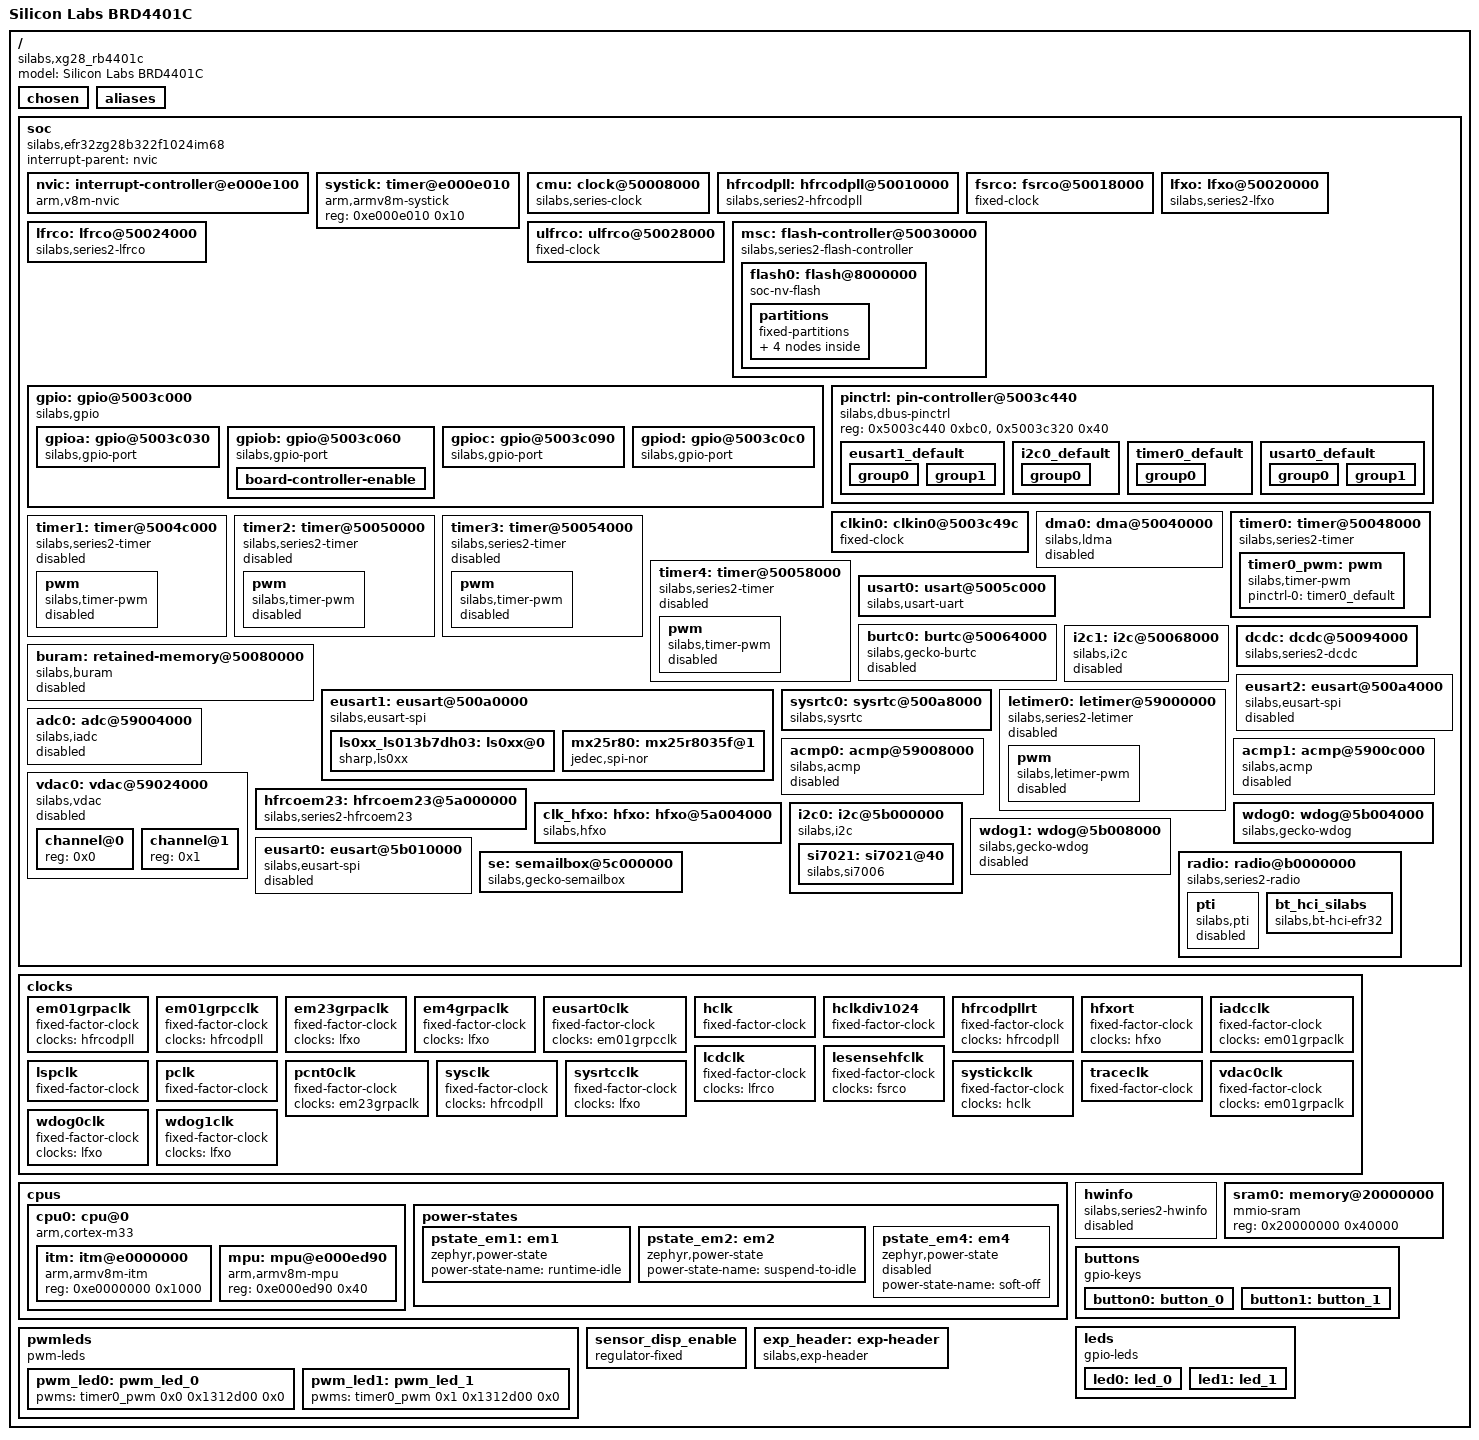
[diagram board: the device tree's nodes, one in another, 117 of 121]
/dts-v1/;

/* node '/' defined in zephyr/dts/common/skeleton.dtsi:9 */
/ {
	#address-cells = < 0x1 >;           /* in zephyr/dts/common/skeleton.dtsi:10 */
	#size-cells = < 0x1 >;              /* in zephyr/dts/common/skeleton.dtsi:11 */
	model = "Silicon Labs BRD4401C";    /* in zephyr/boards/silabs/radio_boards/xg28_rb4401c/xg28_rb4401c.dts:15 */
	compatible = "silabs,xg28_rb4401c",
	             "silabs,efr32zg28";    /* in zephyr/boards/silabs/radio_boards/xg28_rb4401c/xg28_rb4401c.dts:16 */

	/* node '/chosen' defined in zephyr/dts/common/skeleton.dtsi:13 */
	chosen {
		silabs,sleeptimer = &sysrtc0;             /* in zephyr/dts/arm/silabs/xg28/xg28.dtsi:18 */
		zephyr,entropy = &se;                     /* in zephyr/dts/arm/silabs/xg28/xg28.dtsi:19 */
		zephyr,flash-controller = &msc;           /* in zephyr/dts/arm/silabs/xg28/xg28.dtsi:20 */
		zephyr,bt-hci = &bt_hci_silabs;           /* in zephyr/boards/silabs/radio_boards/xg28_rb4401c/xg28_rb4401c.dts:19 */
		zephyr,code-partition = &slot0_partition; /* in zephyr/boards/silabs/radio_boards/xg28_rb4401c/xg28_rb4401c.dts:20 */
		zephyr,console = &usart0;                 /* in zephyr/boards/silabs/radio_boards/xg28_rb4401c/xg28_rb4401c.dts:21 */
		zephyr,display = &ls0xx_ls013b7dh03;      /* in zephyr/boards/silabs/radio_boards/xg28_rb4401c/xg28_rb4401c.dts:22 */
		zephyr,flash = &flash0;                   /* in zephyr/boards/silabs/radio_boards/xg28_rb4401c/xg28_rb4401c.dts:23 */
		zephyr,shell-uart = &usart0;              /* in zephyr/boards/silabs/radio_boards/xg28_rb4401c/xg28_rb4401c.dts:24 */
		zephyr,sram = &sram0;                     /* in zephyr/boards/silabs/radio_boards/xg28_rb4401c/xg28_rb4401c.dts:25 */
		zephyr,uart-pipe = &usart0;               /* in zephyr/boards/silabs/radio_boards/xg28_rb4401c/xg28_rb4401c.dts:26 */
	};

	/* node '/aliases' defined in zephyr/dts/common/skeleton.dtsi:15 */
	aliases {
		dht0 = &si7021;       /* in zephyr/boards/silabs/radio_boards/xg28_rb4401c/xg28_rb4401c.dts:30 */
		led0 = &led0;         /* in zephyr/boards/silabs/radio_boards/xg28_rb4401c/xg28_rb4401c.dts:31 */
		led1 = &led1;         /* in zephyr/boards/silabs/radio_boards/xg28_rb4401c/xg28_rb4401c.dts:32 */
		pwm-led0 = &pwm_led0; /* in zephyr/boards/silabs/radio_boards/xg28_rb4401c/xg28_rb4401c.dts:33 */
		pwm-led1 = &pwm_led1; /* in zephyr/boards/silabs/radio_boards/xg28_rb4401c/xg28_rb4401c.dts:34 */
		sw0 = &button0;       /* in zephyr/boards/silabs/radio_boards/xg28_rb4401c/xg28_rb4401c.dts:35 */
		sw1 = &button1;       /* in zephyr/boards/silabs/radio_boards/xg28_rb4401c/xg28_rb4401c.dts:36 */
		watchdog0 = &wdog0;   /* in zephyr/boards/silabs/radio_boards/xg28_rb4401c/xg28_rb4401c.dts:37 */
	};

	/* node '/soc' defined in zephyr/dts/arm/armv8-m.dtsi:6 */
	soc {
		#address-cells = < 0x1 >;                     /* in zephyr/dts/arm/armv8-m.dtsi:7 */
		#size-cells = < 0x1 >;                        /* in zephyr/dts/arm/armv8-m.dtsi:8 */
		interrupt-parent = < &nvic >;                 /* in zephyr/dts/arm/armv8-m.dtsi:10 */
		ranges;                                       /* in zephyr/dts/arm/armv8-m.dtsi:11 */
		compatible = "silabs,efr32zg28b322f1024im68",
		             "silabs,efr32zg28",
		             "silabs,xg28",
		             "silabs,efr32",
		             "simple-bus";                    /* in zephyr/dts/arm/silabs/xg28/efr32zg28b322f1024im68.dtsi:13 */

		/* node '/soc/interrupt-controller@e000e100' defined in zephyr/dts/arm/armv8-m.dtsi:13 */
		nvic: interrupt-controller@e000e100 {
			#address-cells = < 0x1 >;            /* in zephyr/dts/arm/armv8-m.dtsi:14 */
			compatible = "arm,v8m-nvic";         /* in zephyr/dts/arm/armv8-m.dtsi:15 */
			reg = < 0xe000e100 0xc00 >;          /* in zephyr/dts/arm/armv8-m.dtsi:16 */
			interrupt-controller;                /* in zephyr/dts/arm/armv8-m.dtsi:17 */
			#interrupt-cells = < 0x2 >;          /* in zephyr/dts/arm/armv8-m.dtsi:18 */
			arm,num-irq-priority-bits = < 0x4 >; /* in zephyr/dts/arm/silabs/xg28/xg28.dtsi:668 */
			phandle = < 0x1 >;                   /* in zephyr/dts/arm/armv8-m.dtsi:10 */
		};

		/* node '/soc/timer@e000e010' defined in zephyr/dts/arm/armv8-m.dtsi:21 */
		systick: timer@e000e010 {
			compatible = "arm,armv8m-systick"; /* in zephyr/dts/arm/armv8-m.dtsi:22 */
			reg = < 0xe000e010 0x10 >;         /* in zephyr/dts/arm/armv8-m.dtsi:23 */
		};

		/* node '/soc/clock@50008000' defined in zephyr/dts/arm/silabs/xg28/xg28.dtsi:214 */
		cmu: clock@50008000 {
			compatible = "silabs,series-clock"; /* in zephyr/dts/arm/silabs/xg28/xg28.dtsi:215 */
			reg = < 0x50008000 0x4000 >;        /* in zephyr/dts/arm/silabs/xg28/xg28.dtsi:216 */
			#clock-cells = < 0x2 >;             /* in zephyr/dts/arm/silabs/xg28/xg28.dtsi:217 */
			interrupt-names = "cmu";            /* in zephyr/dts/arm/silabs/xg28/xg28.dtsi:218 */
			interrupts = < 0x30 0x2 >;          /* in zephyr/dts/arm/silabs/xg28/xg28.dtsi:219 */
			status = "okay";                    /* in zephyr/dts/arm/silabs/xg28/xg28.dtsi:220 */
			phandle = < 0x3 >;                  /* in zephyr/dts/arm/silabs/xg28/xg28.dtsi:237 */
		};

		/* node '/soc/hfrcodpll@50010000' defined in zephyr/dts/arm/silabs/xg28/xg28.dtsi:223 */
		hfrcodpll: hfrcodpll@50010000 {
			compatible = "silabs,series2-hfrcodpll"; /* in zephyr/dts/arm/silabs/xg28/xg28.dtsi:224 */
			reg = < 0x50010000 0x4000 >;             /* in zephyr/dts/arm/silabs/xg28/xg28.dtsi:225 */
			#clock-cells = < 0x0 >;                  /* in zephyr/dts/arm/silabs/xg28/xg28.dtsi:226 */
			interrupt-names = "hfrco0";              /* in zephyr/dts/arm/silabs/xg28/xg28.dtsi:228 */
			interrupts = < 0x2e 0x2 >;               /* in zephyr/dts/arm/silabs/xg28/xg28.dtsi:229 */
			clock-frequency = < 0x4a62f80 >;         /* in zephyr/boards/silabs/radio_boards/xg28_rb4401c/xg28_rb4401c.dts:212 */
			clocks = < &hfxo >;                      /* in zephyr/boards/silabs/radio_boards/xg28_rb4401c/xg28_rb4401c.dts:213 */
			dpll-n = < 0xeff >;                      /* in zephyr/boards/silabs/radio_boards/xg28_rb4401c/xg28_rb4401c.dts:214 */
			dpll-m = < 0x77f >;                      /* in zephyr/boards/silabs/radio_boards/xg28_rb4401c/xg28_rb4401c.dts:215 */
			dpll-edge = "fall";                      /* in zephyr/boards/silabs/radio_boards/xg28_rb4401c/xg28_rb4401c.dts:216 */
			dpll-lock = "phase";                     /* in zephyr/boards/silabs/radio_boards/xg28_rb4401c/xg28_rb4401c.dts:217 */
			dpll-autorecover;                        /* in zephyr/boards/silabs/radio_boards/xg28_rb4401c/xg28_rb4401c.dts:218 */
			phandle = < 0xa >;                       /* in zephyr/dts/arm/silabs/xg28/xg28.dtsi:27 */
		};

		/* node '/soc/fsrco@50018000' defined in zephyr/dts/arm/silabs/xg28/xg28.dtsi:232 */
		fsrco: fsrco@50018000 {
			compatible = "fixed-clock";      /* in zephyr/dts/arm/silabs/xg28/xg28.dtsi:233 */
			reg = < 0x50018000 0x4000 >;     /* in zephyr/dts/arm/silabs/xg28/xg28.dtsi:234 */
			#clock-cells = < 0x0 >;          /* in zephyr/dts/arm/silabs/xg28/xg28.dtsi:235 */
			clock-frequency = < 0x1312d00 >; /* in zephyr/dts/arm/silabs/xg28/xg28.dtsi:236 */
			clocks = < &cmu 0x15 0x23 >;     /* in zephyr/dts/arm/silabs/xg28/xg28.dtsi:237 */
			phandle = < 0x11 >;              /* in zephyr/dts/arm/silabs/xg28/xg28.dtsi:95 */
		};

		/* node '/soc/lfxo@50020000' defined in zephyr/dts/arm/silabs/xg28/xg28.dtsi:240 */
		lfxo: lfxo@50020000 {
			compatible = "silabs,series2-lfxo"; /* in zephyr/dts/arm/silabs/xg28/xg28.dtsi:241 */
			reg = < 0x50020000 0x4000 >;        /* in zephyr/dts/arm/silabs/xg28/xg28.dtsi:242 */
			#clock-cells = < 0x0 >;             /* in zephyr/dts/arm/silabs/xg28/xg28.dtsi:243 */
			clock-frequency = < 0x8000 >;       /* in zephyr/dts/arm/silabs/xg28/xg28.dtsi:244 */
			clocks = < &cmu 0x17 0x23 >;        /* in zephyr/dts/arm/silabs/xg28/xg28.dtsi:245 */
			interrupt-names = "lfxo";           /* in zephyr/dts/arm/silabs/xg28/xg28.dtsi:247 */
			interrupts = < 0x17 0x2 >;          /* in zephyr/dts/arm/silabs/xg28/xg28.dtsi:248 */
			timeout = < 0x1000 >;               /* in zephyr/dts/arm/silabs/xg28/xg28.dtsi:250 */
			ctune = < 0x2c >;                   /* in zephyr/boards/silabs/radio_boards/xg28_rb4401c/xg28_rb4401c.dts:228 */
			precision = < 0x32 >;               /* in zephyr/boards/silabs/radio_boards/xg28_rb4401c/xg28_rb4401c.dts:229 */
			status = "okay";                    /* in zephyr/boards/silabs/radio_boards/xg28_rb4401c/xg28_rb4401c.dts:230 */
			phandle = < 0xb >;                  /* in zephyr/boards/silabs/radio_boards/xg28_rb4401c/xg28_rb4401c.dts:127 */
		};

		/* node '/soc/lfrco@50024000' defined in zephyr/dts/arm/silabs/xg28/xg28.dtsi:254 */
		lfrco: lfrco@50024000 {
			compatible = "silabs,series2-lfrco"; /* in zephyr/dts/arm/silabs/xg28/xg28.dtsi:255 */
			reg = < 0x50024000 0x4000 >;         /* in zephyr/dts/arm/silabs/xg28/xg28.dtsi:256 */
			#clock-cells = < 0x0 >;              /* in zephyr/dts/arm/silabs/xg28/xg28.dtsi:257 */
			clock-frequency = < 0x8000 >;        /* in zephyr/dts/arm/silabs/xg28/xg28.dtsi:258 */
			clocks = < &cmu 0x16 0x23 >;         /* in zephyr/dts/arm/silabs/xg28/xg28.dtsi:259 */
			interrupt-names = "lfrco";           /* in zephyr/dts/arm/silabs/xg28/xg28.dtsi:260 */
			interrupts = < 0x18 0x2 >;           /* in zephyr/dts/arm/silabs/xg28/xg28.dtsi:261 */
			phandle = < 0x10 >;                  /* in zephyr/dts/arm/silabs/xg28/xg28.dtsi:89 */
		};

		/* node '/soc/ulfrco@50028000' defined in zephyr/dts/arm/silabs/xg28/xg28.dtsi:264 */
		ulfrco: ulfrco@50028000 {
			compatible = "fixed-clock";  /* in zephyr/dts/arm/silabs/xg28/xg28.dtsi:265 */
			reg = < 0x50028000 0x4000 >; /* in zephyr/dts/arm/silabs/xg28/xg28.dtsi:266 */
			#clock-cells = < 0x0 >;      /* in zephyr/dts/arm/silabs/xg28/xg28.dtsi:267 */
			clock-frequency = < 0x3e8 >; /* in zephyr/dts/arm/silabs/xg28/xg28.dtsi:268 */
			clocks = < &cmu 0x18 0x23 >; /* in zephyr/dts/arm/silabs/xg28/xg28.dtsi:269 */
			interrupt-names = "ulfrco";  /* in zephyr/dts/arm/silabs/xg28/xg28.dtsi:270 */
			interrupts = < 0x19 0x2 >;   /* in zephyr/dts/arm/silabs/xg28/xg28.dtsi:271 */
		};

		/* node '/soc/flash-controller@50030000' defined in zephyr/dts/arm/silabs/xg28/xg28.dtsi:274 */
		msc: flash-controller@50030000 {
			compatible = "silabs,series2-flash-controller"; /* in zephyr/dts/arm/silabs/xg28/xg28.dtsi:275 */
			reg = < 0x50030000 0x4000 >;                    /* in zephyr/dts/arm/silabs/xg28/xg28.dtsi:276 */
			#address-cells = < 0x1 >;                       /* in zephyr/dts/arm/silabs/xg28/xg28.dtsi:277 */
			#size-cells = < 0x1 >;                          /* in zephyr/dts/arm/silabs/xg28/xg28.dtsi:278 */
			clocks = < &cmu 0x50 0x1 >;                     /* in zephyr/dts/arm/silabs/xg28/xg28.dtsi:279 */
			interrupt-names = "msc";                        /* in zephyr/dts/arm/silabs/xg28/xg28.dtsi:280 */
			interrupts = < 0x33 0x2 >;                      /* in zephyr/dts/arm/silabs/xg28/xg28.dtsi:281 */

			/* node '/soc/flash-controller@50030000/flash@8000000' defined in zephyr/dts/arm/silabs/xg28/xg28.dtsi:283 */
			flash0: flash@8000000 {
				compatible = "soc-nv-flash";   /* in zephyr/dts/arm/silabs/xg28/xg28.dtsi:284 */
				erase-block-size = < 0x2000 >; /* in zephyr/dts/arm/silabs/xg28/xg28.dtsi:285 */
				write-block-size = < 0x4 >;    /* in zephyr/dts/arm/silabs/xg28/xg28.dtsi:286 */
				reg = < 0x8000000 0x100000 >;  /* in zephyr/dts/arm/silabs/xg28/efr32zg28b322f1024im68.dtsi:19 */

				/* node '/soc/flash-controller@50030000/flash@8000000/partitions' defined in zephyr/boards/silabs/radio_boards/xg28_rb4401c/xg28_rb4401c.dts:268 */
				partitions {
					compatible = "fixed-partitions"; /* in zephyr/boards/silabs/radio_boards/xg28_rb4401c/xg28_rb4401c.dts:269 */
					#address-cells = < 0x1 >;        /* in zephyr/boards/silabs/radio_boards/xg28_rb4401c/xg28_rb4401c.dts:270 */
					#size-cells = < 0x1 >;           /* in zephyr/boards/silabs/radio_boards/xg28_rb4401c/xg28_rb4401c.dts:271 */

					/* node '/soc/flash-controller@50030000/flash@8000000/partitions/partition@0' defined in zephyr/boards/silabs/radio_boards/xg28_rb4401c/xg28_rb4401c.dts:274 */
					boot_partition: partition@0 {
						reg = < 0x0 0xc000 >; /* in zephyr/boards/silabs/radio_boards/xg28_rb4401c/xg28_rb4401c.dts:275 */
						label = "mcuboot";    /* in zephyr/boards/silabs/radio_boards/xg28_rb4401c/xg28_rb4401c.dts:276 */
						read-only;            /* in zephyr/boards/silabs/radio_boards/xg28_rb4401c/xg28_rb4401c.dts:277 */
					};

					/* node '/soc/flash-controller@50030000/flash@8000000/partitions/partition@c000' defined in zephyr/boards/silabs/radio_boards/xg28_rb4401c/xg28_rb4401c.dts:281 */
					slot0_partition: partition@c000 {
						reg = < 0xc000 0x76000 >; /* in zephyr/boards/silabs/radio_boards/xg28_rb4401c/xg28_rb4401c.dts:282 */
						label = "image-0";        /* in zephyr/boards/silabs/radio_boards/xg28_rb4401c/xg28_rb4401c.dts:283 */
					};

					/* node '/soc/flash-controller@50030000/flash@8000000/partitions/partition@82000' defined in zephyr/boards/silabs/radio_boards/xg28_rb4401c/xg28_rb4401c.dts:287 */
					slot1_partition: partition@82000 {
						reg = < 0x82000 0x76000 >; /* in zephyr/boards/silabs/radio_boards/xg28_rb4401c/xg28_rb4401c.dts:288 */
						label = "image-1";         /* in zephyr/boards/silabs/radio_boards/xg28_rb4401c/xg28_rb4401c.dts:289 */
					};

					/* node '/soc/flash-controller@50030000/flash@8000000/partitions/partition@f8000' defined in zephyr/boards/silabs/radio_boards/xg28_rb4401c/xg28_rb4401c.dts:293 */
					storage_partition: partition@f8000 {
						reg = < 0xf8000 0x8000 >; /* in zephyr/boards/silabs/radio_boards/xg28_rb4401c/xg28_rb4401c.dts:294 */
						label = "storage";        /* in zephyr/boards/silabs/radio_boards/xg28_rb4401c/xg28_rb4401c.dts:295 */
					};
				};
			};
		};

		/* node '/soc/gpio@5003c000' defined in zephyr/dts/arm/silabs/xg28/xg28.dtsi:290 */
		gpio: gpio@5003c000 {
			compatible = "silabs,gpio";    /* in zephyr/dts/arm/silabs/xg28/xg28.dtsi:291 */
			reg = < 0x5003c000 0x4000 >;   /* in zephyr/dts/arm/silabs/xg28/xg28.dtsi:292 */
			ranges;                        /* in zephyr/dts/arm/silabs/xg28/xg28.dtsi:293 */
			#address-cells = < 0x1 >;      /* in zephyr/dts/arm/silabs/xg28/xg28.dtsi:294 */
			#size-cells = < 0x1 >;         /* in zephyr/dts/arm/silabs/xg28/xg28.dtsi:295 */
			clocks = < &cmu 0x1a 0x3 >;    /* in zephyr/dts/arm/silabs/xg28/xg28.dtsi:296 */
			interrupt-names = "gpio_odd",
			                  "gpio_even"; /* in zephyr/dts/arm/silabs/xg28/xg28.dtsi:297 */
			interrupts = < 0x1a 0x2 >,
			             < 0x1b 0x2 >;     /* in zephyr/dts/arm/silabs/xg28/xg28.dtsi:298 */
			status = "okay";               /* in zephyr/boards/silabs/radio_boards/xg28_rb4401c/xg28_rb4401c.dts:186 */

			/* node '/soc/gpio@5003c000/gpio@5003c030' defined in zephyr/dts/arm/silabs/xg28/xg28.dtsi:300 */
			gpioa: gpio@5003c030 {
				compatible = "silabs,gpio-port"; /* in zephyr/dts/arm/silabs/xg28/xg28.dtsi:301 */
				reg = < 0x5003c030 0x30 >;       /* in zephyr/dts/arm/silabs/xg28/xg28.dtsi:302 */
				#gpio-cells = < 0x2 >;           /* in zephyr/dts/arm/silabs/xg28/xg28.dtsi:303 */
				gpio-controller;                 /* in zephyr/dts/arm/silabs/xg28/xg28.dtsi:304 */
				silabs,wakeup-ints = < 0x0 >;    /* in zephyr/dts/arm/silabs/xg28/xg28.dtsi:305 */
				silabs,wakeup-pins = < 0x5 >;    /* in zephyr/dts/arm/silabs/xg28/xg28.dtsi:306 */
				status = "okay";                 /* in zephyr/boards/silabs/radio_boards/xg28_rb4401c/xg28_rb4401c.dts:190 */
				phandle = < 0x1a >;              /* in zephyr/boards/silabs/radio_boards/xg28_rb4401c/xg28_rb4401c.dts:92 */
			};

			/* node '/soc/gpio@5003c000/gpio@5003c060' defined in zephyr/dts/arm/silabs/xg28/xg28.dtsi:310 */
			gpiob: gpio@5003c060 {
				compatible = "silabs,gpio-port"; /* in zephyr/dts/arm/silabs/xg28/xg28.dtsi:311 */
				reg = < 0x5003c060 0x30 >;       /* in zephyr/dts/arm/silabs/xg28/xg28.dtsi:312 */
				#gpio-cells = < 0x2 >;           /* in zephyr/dts/arm/silabs/xg28/xg28.dtsi:313 */
				gpio-controller;                 /* in zephyr/dts/arm/silabs/xg28/xg28.dtsi:314 */
				silabs,wakeup-ints = < 0x3 >,
				                     < 0x4 >;    /* in zephyr/dts/arm/silabs/xg28/xg28.dtsi:315 */
				silabs,wakeup-pins = < 0x1 >,
				                     < 0x3 >;    /* in zephyr/dts/arm/silabs/xg28/xg28.dtsi:316 */
				status = "okay";                 /* in zephyr/boards/silabs/radio_boards/xg28_rb4401c/xg28_rb4401c.dts:194 */
				phandle = < 0x17 >;              /* in zephyr/boards/silabs/radio_boards/xg28_rb4401c/xg28_rb4401c.dts:44 */

				/* node '/soc/gpio@5003c000/gpio@5003c060/board-controller-enable' defined in zephyr/boards/silabs/radio_boards/xg28_rb4401c/xg28_rb4401c.dts:196 */
				board-controller-enable {
					gpio-hog;            /* in zephyr/boards/silabs/radio_boards/xg28_rb4401c/xg28_rb4401c.dts:197 */
					gpios = < 0x0 0x0 >; /* in zephyr/boards/silabs/radio_boards/xg28_rb4401c/xg28_rb4401c.dts:198 */
					output-high;         /* in zephyr/boards/silabs/radio_boards/xg28_rb4401c/xg28_rb4401c.dts:199 */
				};
			};

			/* node '/soc/gpio@5003c000/gpio@5003c090' defined in zephyr/dts/arm/silabs/xg28/xg28.dtsi:320 */
			gpioc: gpio@5003c090 {
				compatible = "silabs,gpio-port"; /* in zephyr/dts/arm/silabs/xg28/xg28.dtsi:321 */
				reg = < 0x5003c090 0x30 >;       /* in zephyr/dts/arm/silabs/xg28/xg28.dtsi:322 */
				#gpio-cells = < 0x2 >;           /* in zephyr/dts/arm/silabs/xg28/xg28.dtsi:323 */
				gpio-controller;                 /* in zephyr/dts/arm/silabs/xg28/xg28.dtsi:324 */
				silabs,wakeup-ints = < 0x6 >,
				                     < 0x7 >,
				                     < 0x8 >;    /* in zephyr/dts/arm/silabs/xg28/xg28.dtsi:325 */
				silabs,wakeup-pins = < 0x0 >,
				                     < 0x5 >,
				                     < 0x7 >;    /* in zephyr/dts/arm/silabs/xg28/xg28.dtsi:326 */
				status = "okay";                 /* in zephyr/boards/silabs/radio_boards/xg28_rb4401c/xg28_rb4401c.dts:204 */
				phandle = < 0x7 >;               /* in zephyr/boards/silabs/radio_boards/xg28_rb4401c/xg28_rb4401c.dts:139 */
			};

			/* node '/soc/gpio@5003c000/gpio@5003c0c0' defined in zephyr/dts/arm/silabs/xg28/xg28.dtsi:330 */
			gpiod: gpio@5003c0c0 {
				compatible = "silabs,gpio-port"; /* in zephyr/dts/arm/silabs/xg28/xg28.dtsi:331 */
				reg = < 0x5003c0c0 0x30 >;       /* in zephyr/dts/arm/silabs/xg28/xg28.dtsi:332 */
				#gpio-cells = < 0x2 >;           /* in zephyr/dts/arm/silabs/xg28/xg28.dtsi:333 */
				gpio-controller;                 /* in zephyr/dts/arm/silabs/xg28/xg28.dtsi:334 */
				silabs,wakeup-ints = < 0xa >,
				                     < 0x9 >;    /* in zephyr/dts/arm/silabs/xg28/xg28.dtsi:335 */
				silabs,wakeup-pins = < 0x5 >,
				                     < 0x2 >;    /* in zephyr/dts/arm/silabs/xg28/xg28.dtsi:336 */
				status = "okay";                 /* in zephyr/boards/silabs/radio_boards/xg28_rb4401c/xg28_rb4401c.dts:208 */
				phandle = < 0x18 >;              /* in zephyr/boards/silabs/radio_boards/xg28_rb4401c/xg28_rb4401c.dts:65 */
			};
		};

		/* node '/soc/pin-controller@5003c440' defined in zephyr/dts/arm/silabs/xg28/xg28.dtsi:341 */
		pinctrl: pin-controller@5003c440 {
			compatible = "silabs,dbus-pinctrl"; /* in zephyr/dts/arm/silabs/xg28/xg28.dtsi:342 */
			reg = < 0x5003c440 0xbc0 >,
			      < 0x5003c320 0x40 >;          /* in zephyr/dts/arm/silabs/xg28/xg28.dtsi:343 */
			reg-names = "dbus",
			            "abus";                 /* in zephyr/dts/arm/silabs/xg28/xg28.dtsi:344 */

			/* node '/soc/pin-controller@5003c440/eusart1_default' defined in zephyr/boards/silabs/radio_boards/xg28_rb4401c/xg28_rb4401c-pinctrl.dtsi:10 */
			eusart1_default: eusart1_default {
				phandle = < 0x6 >; /* in zephyr/boards/silabs/radio_boards/xg28_rb4401c/xg28_rb4401c.dts:137 */

				/* node '/soc/pin-controller@5003c440/eusart1_default/group0' defined in zephyr/boards/silabs/radio_boards/xg28_rb4401c/xg28_rb4401c-pinctrl.dtsi:11 */
				group0 {
					pins = < 0x26242912 >,
					       < 0x251c2932 >; /* in zephyr/boards/silabs/radio_boards/xg28_rb4401c/xg28_rb4401c-pinctrl.dtsi:12 */
					drive-push-pull;       /* in zephyr/boards/silabs/radio_boards/xg28_rb4401c/xg28_rb4401c-pinctrl.dtsi:13 */
					output-high;           /* in zephyr/boards/silabs/radio_boards/xg28_rb4401c/xg28_rb4401c-pinctrl.dtsi:14 */
				};

				/* node '/soc/pin-controller@5003c440/eusart1_default/group1' defined in zephyr/boards/silabs/radio_boards/xg28_rb4401c/xg28_rb4401c-pinctrl.dtsi:17 */
				group1 {
					pins = < 0x24142922 >; /* in zephyr/boards/silabs/radio_boards/xg28_rb4401c/xg28_rb4401c-pinctrl.dtsi:18 */
					input-enable;          /* in zephyr/boards/silabs/radio_boards/xg28_rb4401c/xg28_rb4401c-pinctrl.dtsi:19 */
					silabs,input-filter;   /* in zephyr/boards/silabs/radio_boards/xg28_rb4401c/xg28_rb4401c-pinctrl.dtsi:20 */
				};
			};

			/* node '/soc/pin-controller@5003c440/i2c0_default' defined in zephyr/boards/silabs/radio_boards/xg28_rb4401c/xg28_rb4401c-pinctrl.dtsi:24 */
			i2c0_default: i2c0_default {
				phandle = < 0x8 >; /* in zephyr/boards/silabs/radio_boards/xg28_rb4401c/xg28_rb4401c.dts:174 */

				/* node '/soc/pin-controller@5003c440/i2c0_default/group0' defined in zephyr/boards/silabs/radio_boards/xg28_rb4401c/xg28_rb4401c-pinctrl.dtsi:25 */
				group0 {
					pins = < 0x21043e52 >,
					       < 0x220c3e72 >; /* in zephyr/boards/silabs/radio_boards/xg28_rb4401c/xg28_rb4401c-pinctrl.dtsi:26 */
					drive-open-drain;      /* in zephyr/boards/silabs/radio_boards/xg28_rb4401c/xg28_rb4401c-pinctrl.dtsi:27 */
					bias-pull-up;          /* in zephyr/boards/silabs/radio_boards/xg28_rb4401c/xg28_rb4401c-pinctrl.dtsi:28 */
				};
			};

			/* node '/soc/pin-controller@5003c440/timer0_default' defined in zephyr/boards/silabs/radio_boards/xg28_rb4401c/xg28_rb4401c-pinctrl.dtsi:32 */
			timer0_default: timer0_default {
				phandle = < 0x4 >; /* in zephyr/boards/silabs/radio_boards/xg28_rb4401c/xg28_rb4401c.dts:249 */

				/* node '/soc/pin-controller@5003c440/timer0_default/group0' defined in zephyr/boards/silabs/radio_boards/xg28_rb4401c/xg28_rb4401c-pinctrl.dtsi:33 */
				group0 {
					pins = < 0x2104ae21 >,
					       < 0x220cae33 >; /* in zephyr/boards/silabs/radio_boards/xg28_rb4401c/xg28_rb4401c-pinctrl.dtsi:34 */
					drive-push-pull;       /* in zephyr/boards/silabs/radio_boards/xg28_rb4401c/xg28_rb4401c-pinctrl.dtsi:35 */
					output-high;           /* in zephyr/boards/silabs/radio_boards/xg28_rb4401c/xg28_rb4401c-pinctrl.dtsi:36 */
				};
			};

			/* node '/soc/pin-controller@5003c440/usart0_default' defined in zephyr/boards/silabs/radio_boards/xg28_rb4401c/xg28_rb4401c-pinctrl.dtsi:40 */
			usart0_default: usart0_default {
				phandle = < 0x5 >; /* in zephyr/boards/silabs/radio_boards/xg28_rb4401c/xg28_rb4401c.dts:168 */

				/* node '/soc/pin-controller@5003c440/usart0_default/group0' defined in zephyr/boards/silabs/radio_boards/xg28_rb4401c/xg28_rb4401c-pinctrl.dtsi:41 */
				group0 {
					pins = < 0x2624d680 >; /* in zephyr/boards/silabs/radio_boards/xg28_rb4401c/xg28_rb4401c-pinctrl.dtsi:42 */
					drive-push-pull;       /* in zephyr/boards/silabs/radio_boards/xg28_rb4401c/xg28_rb4401c-pinctrl.dtsi:43 */
					output-high;           /* in zephyr/boards/silabs/radio_boards/xg28_rb4401c/xg28_rb4401c-pinctrl.dtsi:44 */
				};

				/* node '/soc/pin-controller@5003c440/usart0_default/group1' defined in zephyr/boards/silabs/radio_boards/xg28_rb4401c/xg28_rb4401c-pinctrl.dtsi:47 */
				group1 {
					pins = < 0x2414d690 >; /* in zephyr/boards/silabs/radio_boards/xg28_rb4401c/xg28_rb4401c-pinctrl.dtsi:48 */
					input-enable;          /* in zephyr/boards/silabs/radio_boards/xg28_rb4401c/xg28_rb4401c-pinctrl.dtsi:49 */
					silabs,input-filter;   /* in zephyr/boards/silabs/radio_boards/xg28_rb4401c/xg28_rb4401c-pinctrl.dtsi:50 */
				};
			};
		};

		/* node '/soc/clkin0@5003c49c' defined in zephyr/dts/arm/silabs/xg28/xg28.dtsi:347 */
		clkin0: clkin0@5003c49c {
			compatible = "fixed-clock";      /* in zephyr/dts/arm/silabs/xg28/xg28.dtsi:348 */
			reg = < 0x5003c49c 0x4 >;        /* in zephyr/dts/arm/silabs/xg28/xg28.dtsi:349 */
			#clock-cells = < 0x0 >;          /* in zephyr/dts/arm/silabs/xg28/xg28.dtsi:350 */
			clock-frequency = < 0x243d580 >; /* in zephyr/dts/arm/silabs/xg28/xg28.dtsi:351 */
		};

		/* node '/soc/dma@50040000' defined in zephyr/dts/arm/silabs/xg28/xg28.dtsi:354 */
		dma0: dma@50040000 {
			compatible = "silabs,ldma";  /* in zephyr/dts/arm/silabs/xg28/xg28.dtsi:355 */
			reg = < 0x50040000 0x4000 >; /* in zephyr/dts/arm/silabs/xg28/xg28.dtsi:356 */
			#dma-cells = < 0x1 >;        /* in zephyr/dts/arm/silabs/xg28/xg28.dtsi:357 */
			clocks = < &cmu 0x0 0x1 >;   /* in zephyr/dts/arm/silabs/xg28/xg28.dtsi:358 */
			dma-channels = < 0x8 >;      /* in zephyr/dts/arm/silabs/xg28/xg28.dtsi:359 */
			interrupt-names = "ldma";    /* in zephyr/dts/arm/silabs/xg28/xg28.dtsi:360 */
			interrupts = < 0x16 0x2 >;   /* in zephyr/dts/arm/silabs/xg28/xg28.dtsi:361 */
			status = "disabled";         /* in zephyr/dts/arm/silabs/xg28/xg28.dtsi:362 */
		};

		/* node '/soc/timer@50048000' defined in zephyr/dts/arm/silabs/xg28/xg28.dtsi:365 */
		timer0: timer@50048000 {
			compatible = "silabs,series2-timer"; /* in zephyr/dts/arm/silabs/xg28/xg28.dtsi:366 */
			reg = < 0x50048000 0x4000 >;         /* in zephyr/dts/arm/silabs/xg28/xg28.dtsi:367 */
			channels = < 0x3 >;                  /* in zephyr/dts/arm/silabs/xg28/xg28.dtsi:368 */
			clocks = < &cmu 0x4 0x8 >;           /* in zephyr/dts/arm/silabs/xg28/xg28.dtsi:369 */
			counter-size = < 0x20 >;             /* in zephyr/dts/arm/silabs/xg28/xg28.dtsi:370 */
			interrupt-names = "timer0";          /* in zephyr/dts/arm/silabs/xg28/xg28.dtsi:371 */
			interrupts = < 0x4 0x2 >;            /* in zephyr/dts/arm/silabs/xg28/xg28.dtsi:372 */
			status = "okay";                     /* in zephyr/boards/silabs/radio_boards/xg28_rb4401c/xg28_rb4401c.dts:246 */

			/* node '/soc/timer@50048000/pwm' defined in zephyr/dts/arm/silabs/xg28/xg28.dtsi:375 */
			timer0_pwm: pwm {
				compatible = "silabs,timer-pwm"; /* in zephyr/dts/arm/silabs/xg28/xg28.dtsi:376 */
				#pwm-cells = < 0x3 >;            /* in zephyr/dts/arm/silabs/xg28/xg28.dtsi:377 */
				pinctrl-0 = < &timer0_default >; /* in zephyr/boards/silabs/radio_boards/xg28_rb4401c/xg28_rb4401c.dts:249 */
				pinctrl-names = "default";       /* in zephyr/boards/silabs/radio_boards/xg28_rb4401c/xg28_rb4401c.dts:250 */
				status = "okay";                 /* in zephyr/boards/silabs/radio_boards/xg28_rb4401c/xg28_rb4401c.dts:251 */
				phandle = < 0x19 >;              /* in zephyr/boards/silabs/radio_boards/xg28_rb4401c/xg28_rb4401c.dts:74 */
			};
		};

		/* node '/soc/timer@5004c000' defined in zephyr/dts/arm/silabs/xg28/xg28.dtsi:382 */
		timer1: timer@5004c000 {
			compatible = "silabs,series2-timer"; /* in zephyr/dts/arm/silabs/xg28/xg28.dtsi:383 */
			reg = < 0x5004c000 0x4000 >;         /* in zephyr/dts/arm/silabs/xg28/xg28.dtsi:384 */
			channels = < 0x3 >;                  /* in zephyr/dts/arm/silabs/xg28/xg28.dtsi:385 */
			clocks = < &cmu 0x5 0x8 >;           /* in zephyr/dts/arm/silabs/xg28/xg28.dtsi:386 */
			counter-size = < 0x10 >;             /* in zephyr/dts/arm/silabs/xg28/xg28.dtsi:387 */
			interrupt-names = "timer1";          /* in zephyr/dts/arm/silabs/xg28/xg28.dtsi:388 */
			interrupts = < 0x5 0x2 >;            /* in zephyr/dts/arm/silabs/xg28/xg28.dtsi:389 */
			status = "disabled";                 /* in zephyr/dts/arm/silabs/xg28/xg28.dtsi:390 */

			/* node '/soc/timer@5004c000/pwm' defined in zephyr/dts/arm/silabs/xg28/xg28.dtsi:392 */
			pwm {
				compatible = "silabs,timer-pwm"; /* in zephyr/dts/arm/silabs/xg28/xg28.dtsi:393 */
				#pwm-cells = < 0x3 >;            /* in zephyr/dts/arm/silabs/xg28/xg28.dtsi:394 */
				status = "disabled";             /* in zephyr/dts/arm/silabs/xg28/xg28.dtsi:395 */
			};
		};

		/* node '/soc/timer@50050000' defined in zephyr/dts/arm/silabs/xg28/xg28.dtsi:399 */
		timer2: timer@50050000 {
			compatible = "silabs,series2-timer"; /* in zephyr/dts/arm/silabs/xg28/xg28.dtsi:400 */
			reg = < 0x50050000 0x4000 >;         /* in zephyr/dts/arm/silabs/xg28/xg28.dtsi:401 */
			channels = < 0x3 >;                  /* in zephyr/dts/arm/silabs/xg28/xg28.dtsi:402 */
			clocks = < &cmu 0x6 0x8 >;           /* in zephyr/dts/arm/silabs/xg28/xg28.dtsi:403 */
			counter-size = < 0x10 >;             /* in zephyr/dts/arm/silabs/xg28/xg28.dtsi:404 */
			interrupt-names = "timer2";          /* in zephyr/dts/arm/silabs/xg28/xg28.dtsi:405 */
			interrupts = < 0x6 0x2 >;            /* in zephyr/dts/arm/silabs/xg28/xg28.dtsi:406 */
			status = "disabled";                 /* in zephyr/dts/arm/silabs/xg28/xg28.dtsi:407 */

			/* node '/soc/timer@50050000/pwm' defined in zephyr/dts/arm/silabs/xg28/xg28.dtsi:409 */
			pwm {
				compatible = "silabs,timer-pwm"; /* in zephyr/dts/arm/silabs/xg28/xg28.dtsi:410 */
				#pwm-cells = < 0x3 >;            /* in zephyr/dts/arm/silabs/xg28/xg28.dtsi:411 */
				status = "disabled";             /* in zephyr/dts/arm/silabs/xg28/xg28.dtsi:412 */
			};
		};

		/* node '/soc/timer@50054000' defined in zephyr/dts/arm/silabs/xg28/xg28.dtsi:416 */
		timer3: timer@50054000 {
			compatible = "silabs,series2-timer"; /* in zephyr/dts/arm/silabs/xg28/xg28.dtsi:417 */
			reg = < 0x50054000 0x4000 >;         /* in zephyr/dts/arm/silabs/xg28/xg28.dtsi:418 */
			channels = < 0x3 >;                  /* in zephyr/dts/arm/silabs/xg28/xg28.dtsi:419 */
			clocks = < &cmu 0x7 0x8 >;           /* in zephyr/dts/arm/silabs/xg28/xg28.dtsi:420 */
			counter-size = < 0x10 >;             /* in zephyr/dts/arm/silabs/xg28/xg28.dtsi:421 */
			interrupt-names = "timer3";          /* in zephyr/dts/arm/silabs/xg28/xg28.dtsi:422 */
			interrupts = < 0x7 0x2 >;            /* in zephyr/dts/arm/silabs/xg28/xg28.dtsi:423 */
			status = "disabled";                 /* in zephyr/dts/arm/silabs/xg28/xg28.dtsi:424 */

			/* node '/soc/timer@50054000/pwm' defined in zephyr/dts/arm/silabs/xg28/xg28.dtsi:426 */
			pwm {
				compatible = "silabs,timer-pwm"; /* in zephyr/dts/arm/silabs/xg28/xg28.dtsi:427 */
				#pwm-cells = < 0x3 >;            /* in zephyr/dts/arm/silabs/xg28/xg28.dtsi:428 */
				status = "disabled";             /* in zephyr/dts/arm/silabs/xg28/xg28.dtsi:429 */
			};
		};

		/* node '/soc/timer@50058000' defined in zephyr/dts/arm/silabs/xg28/xg28.dtsi:433 */
		timer4: timer@50058000 {
			compatible = "silabs,series2-timer"; /* in zephyr/dts/arm/silabs/xg28/xg28.dtsi:434 */
			reg = < 0x50058000 0x4000 >;         /* in zephyr/dts/arm/silabs/xg28/xg28.dtsi:435 */
			channels = < 0x3 >;                  /* in zephyr/dts/arm/silabs/xg28/xg28.dtsi:436 */
			clocks = < &cmu 0x8 0x8 >;           /* in zephyr/dts/arm/silabs/xg28/xg28.dtsi:437 */
			counter-size = < 0x10 >;             /* in zephyr/dts/arm/silabs/xg28/xg28.dtsi:438 */
			interrupt-names = "timer4";          /* in zephyr/dts/arm/silabs/xg28/xg28.dtsi:439 */
			interrupts = < 0x8 0x2 >;            /* in zephyr/dts/arm/silabs/xg28/xg28.dtsi:440 */
			status = "disabled";                 /* in zephyr/dts/arm/silabs/xg28/xg28.dtsi:441 */

			/* node '/soc/timer@50058000/pwm' defined in zephyr/dts/arm/silabs/xg28/xg28.dtsi:443 */
			pwm {
				compatible = "silabs,timer-pwm"; /* in zephyr/dts/arm/silabs/xg28/xg28.dtsi:444 */
				#pwm-cells = < 0x3 >;            /* in zephyr/dts/arm/silabs/xg28/xg28.dtsi:445 */
				status = "disabled";             /* in zephyr/dts/arm/silabs/xg28/xg28.dtsi:446 */
			};
		};

		/* node '/soc/usart@5005c000' defined in zephyr/dts/arm/silabs/xg28/xg28.dtsi:450 */
		usart0: usart@5005c000 {
			compatible = "silabs,usart-uart"; /* in zephyr/dts/arm/silabs/xg28/xg28.dtsi:451 */
			reg = < 0x5005c000 0x4000 >;      /* in zephyr/dts/arm/silabs/xg28/xg28.dtsi:452 */
			clocks = < &cmu 0x9 0x3 >;        /* in zephyr/dts/arm/silabs/xg28/xg28.dtsi:453 */
			interrupt-names = "rx",
			                  "tx";           /* in zephyr/dts/arm/silabs/xg28/xg28.dtsi:454 */
			interrupts = < 0x9 0x2 >,
			             < 0xa 0x2 >;         /* in zephyr/dts/arm/silabs/xg28/xg28.dtsi:455 */
			current-speed = < 0x1c200 >;      /* in zephyr/boards/silabs/radio_boards/xg28_rb4401c/xg28_rb4401c.dts:167 */
			pinctrl-0 = < &usart0_default >;  /* in zephyr/boards/silabs/radio_boards/xg28_rb4401c/xg28_rb4401c.dts:168 */
			pinctrl-names = "default";        /* in zephyr/boards/silabs/radio_boards/xg28_rb4401c/xg28_rb4401c.dts:169 */
			status = "okay";                  /* in zephyr/boards/silabs/radio_boards/xg28_rb4401c/xg28_rb4401c.dts:170 */
		};

		/* node '/soc/burtc@50064000' defined in zephyr/dts/arm/silabs/xg28/xg28.dtsi:459 */
		burtc0: burtc@50064000 {
			compatible = "silabs,gecko-burtc"; /* in zephyr/dts/arm/silabs/xg28/xg28.dtsi:460 */
			reg = < 0x50064000 0x4000 >;       /* in zephyr/dts/arm/silabs/xg28/xg28.dtsi:461 */
			clocks = < &cmu 0x1d 0xd >;        /* in zephyr/dts/arm/silabs/xg28/xg28.dtsi:462 */
			interrupt-names = "burtc";         /* in zephyr/dts/arm/silabs/xg28/xg28.dtsi:463 */
			interrupts = < 0x12 0x2 >;         /* in zephyr/dts/arm/silabs/xg28/xg28.dtsi:464 */
			status = "disabled";               /* in zephyr/dts/arm/silabs/xg28/xg28.dtsi:465 */
		};

		/* node '/soc/i2c@50068000' defined in zephyr/dts/arm/silabs/xg28/xg28.dtsi:468 */
		i2c1: i2c@50068000 {
			compatible = "silabs,i2c";     /* in zephyr/dts/arm/silabs/xg28/xg28.dtsi:469 */
			reg = < 0x50068000 0x4000 >;   /* in zephyr/dts/arm/silabs/xg28/xg28.dtsi:470 */
			#address-cells = < 0x1 >;      /* in zephyr/dts/arm/silabs/xg28/xg28.dtsi:471 */
			#size-cells = < 0x0 >;         /* in zephyr/dts/arm/silabs/xg28/xg28.dtsi:472 */
			clock-frequency = < 0x186a0 >; /* in zephyr/dts/arm/silabs/xg28/xg28.dtsi:473 */
			clocks = < &cmu 0xf 0x3 >;     /* in zephyr/dts/arm/silabs/xg28/xg28.dtsi:474 */
			interrupt-names = "i2c1";      /* in zephyr/dts/arm/silabs/xg28/xg28.dtsi:475 */
			interrupts = < 0x1d 0x2 >;     /* in zephyr/dts/arm/silabs/xg28/xg28.dtsi:476 */
			status = "disabled";           /* in zephyr/dts/arm/silabs/xg28/xg28.dtsi:477 */
		};

		/* node '/soc/retained-memory@50080000' defined in zephyr/dts/arm/silabs/xg28/xg28.dtsi:480 */
		buram: retained-memory@50080000 {
			compatible = "silabs,buram"; /* in zephyr/dts/arm/silabs/xg28/xg28.dtsi:481 */
			reg = < 0x50080000 0x80 >;   /* in zephyr/dts/arm/silabs/xg28/xg28.dtsi:482 */
			clocks = < &cmu 0x1c 0x23 >; /* in zephyr/dts/arm/silabs/xg28/xg28.dtsi:483 */
			status = "disabled";         /* in zephyr/dts/arm/silabs/xg28/xg28.dtsi:484 */
		};

		/* node '/soc/dcdc@50094000' defined in zephyr/dts/arm/silabs/xg28/xg28.dtsi:487 */
		dcdc: dcdc@50094000 {
			compatible = "silabs,series2-dcdc";           /* in zephyr/dts/arm/silabs/xg28/xg28.dtsi:488 */
			reg = < 0x50094000 0x4000 >;                  /* in zephyr/dts/arm/silabs/xg28/xg28.dtsi:489 */
			clocks = < &cmu 0x1f 0x23 >;                  /* in zephyr/dts/arm/silabs/xg28/xg28.dtsi:490 */
			interrupt-names = "dcdc";                     /* in zephyr/dts/arm/silabs/xg28/xg28.dtsi:491 */
			interrupts = < 0x36 0x2 >;                    /* in zephyr/dts/arm/silabs/xg28/xg28.dtsi:492 */
			regulator-boot-on;                            /* in zephyr/boards/silabs/radio_boards/xg28_rb4401c/xg28_rb4401c.dts:120 */
			regulator-initial-mode = < 0x0 >;             /* in zephyr/boards/silabs/radio_boards/xg28_rb4401c/xg28_rb4401c.dts:121 */
			silabs,pfmx-peak-current-milliamp = < 0x64 >; /* in zephyr/boards/silabs/radio_boards/xg28_rb4401c/xg28_rb4401c.dts:122 */
			status = "okay";                              /* in zephyr/boards/silabs/radio_boards/xg28_rb4401c/xg28_rb4401c.dts:123 */
		};

		/* node '/soc/eusart@500a0000' defined in zephyr/dts/arm/silabs/xg28/xg28.dtsi:496 */
		eusart1: eusart@500a0000 {
			compatible = "silabs,eusart-spi"; /* in zephyr/dts/arm/silabs/xg28/xg28.dtsi:497 */
			reg = < 0x500a0000 0x4000 >;      /* in zephyr/dts/arm/silabs/xg28/xg28.dtsi:498 */
			clocks = < &cmu 0x57 0xa >;       /* in zephyr/dts/arm/silabs/xg28/xg28.dtsi:499 */
			interrupt-names = "rx",
			                  "tx";           /* in zephyr/dts/arm/silabs/xg28/xg28.dtsi:500 */
			interrupts = < 0xd 0x2 >,
			             < 0xe 0x2 >;         /* in zephyr/dts/arm/silabs/xg28/xg28.dtsi:501 */
			#address-cells = < 0x1 >;         /* in zephyr/boards/silabs/radio_boards/xg28_rb4401c/xg28_rb4401c.dts:135 */
			#size-cells = < 0x0 >;            /* in zephyr/boards/silabs/radio_boards/xg28_rb4401c/xg28_rb4401c.dts:136 */
			pinctrl-0 = < &eusart1_default >; /* in zephyr/boards/silabs/radio_boards/xg28_rb4401c/xg28_rb4401c.dts:137 */
			pinctrl-names = "default";        /* in zephyr/boards/silabs/radio_boards/xg28_rb4401c/xg28_rb4401c.dts:138 */
			cs-gpios = < &gpioc 0x8 0x0 >,
			           < &gpioc 0x4 0x1 >;    /* in zephyr/boards/silabs/radio_boards/xg28_rb4401c/xg28_rb4401c.dts:139 */
			status = "okay";                  /* in zephyr/boards/silabs/radio_boards/xg28_rb4401c/xg28_rb4401c.dts:140 */

			/* node '/soc/eusart@500a0000/ls0xx@0' defined in zephyr/boards/silabs/radio_boards/xg28_rb4401c/xg28_rb4401c.dts:142 */
			ls0xx_ls013b7dh03: ls0xx@0 {
				compatible = "sharp,ls0xx";          /* in zephyr/boards/silabs/radio_boards/xg28_rb4401c/xg28_rb4401c.dts:143 */
				reg = < 0x0 >;                       /* in zephyr/boards/silabs/radio_boards/xg28_rb4401c/xg28_rb4401c.dts:144 */
				disp-en-gpios = < &gpioc 0x9 0x0 >;  /* in zephyr/boards/silabs/radio_boards/xg28_rb4401c/xg28_rb4401c.dts:145 */
				extcomin-gpios = < &gpioc 0x6 0x0 >; /* in zephyr/boards/silabs/radio_boards/xg28_rb4401c/xg28_rb4401c.dts:146 */
				extcomin-frequency = < 0x3c >;       /* in zephyr/boards/silabs/radio_boards/xg28_rb4401c/xg28_rb4401c.dts:147 */
				height = < 0x80 >;                   /* in zephyr/boards/silabs/radio_boards/xg28_rb4401c/xg28_rb4401c.dts:148 */
				width = < 0x80 >;                    /* in zephyr/boards/silabs/radio_boards/xg28_rb4401c/xg28_rb4401c.dts:149 */
				spi-max-frequency = < 0x10c8e0 >;    /* in zephyr/boards/silabs/radio_boards/xg28_rb4401c/xg28_rb4401c.dts:150 */
			};

			/* node '/soc/eusart@500a0000/mx25r8035f@1' defined in zephyr/boards/silabs/radio_boards/xg28_rb4401c/xg28_rb4401c.dts:153 */
			mx25r80: mx25r8035f@1 {
				compatible = "jedec,spi-nor";                 /* in zephyr/boards/silabs/radio_boards/xg28_rb4401c/xg28_rb4401c.dts:154 */
				reg = < 0x1 >;                                /* in zephyr/boards/silabs/radio_boards/xg28_rb4401c/xg28_rb4401c.dts:155 */
				dpd-wakeup-sequence = < 0x7530 0x14 0x88b8 >; /* in zephyr/boards/silabs/radio_boards/xg28_rb4401c/xg28_rb4401c.dts:156 */
				has-dpd;                                      /* in zephyr/boards/silabs/radio_boards/xg28_rb4401c/xg28_rb4401c.dts:157 */
				jedec-id = [ C2 28 14 ];                      /* in zephyr/boards/silabs/radio_boards/xg28_rb4401c/xg28_rb4401c.dts:158 */
				mxicy,mx25r-power-mode = "low-power";         /* in zephyr/boards/silabs/radio_boards/xg28_rb4401c/xg28_rb4401c.dts:159 */
				size = < 0x800000 >;                          /* in zephyr/boards/silabs/radio_boards/xg28_rb4401c/xg28_rb4401c.dts:160 */
				spi-max-frequency = < 0x1f78a40 >;            /* in zephyr/boards/silabs/radio_boards/xg28_rb4401c/xg28_rb4401c.dts:161 */
				t-enter-dpd = < 0x0 >;                        /* in zephyr/boards/silabs/radio_boards/xg28_rb4401c/xg28_rb4401c.dts:162 */
			};
		};

		/* node '/soc/eusart@500a4000' defined in zephyr/dts/arm/silabs/xg28/xg28.dtsi:505 */
		eusart2: eusart@500a4000 {
			compatible = "silabs,eusart-spi"; /* in zephyr/dts/arm/silabs/xg28/xg28.dtsi:506 */
			reg = < 0x500a4000 0x4000 >;      /* in zephyr/dts/arm/silabs/xg28/xg28.dtsi:507 */
			clocks = < &cmu 0x58 0xa >;       /* in zephyr/dts/arm/silabs/xg28/xg28.dtsi:508 */
			interrupt-names = "rx",
			                  "tx";           /* in zephyr/dts/arm/silabs/xg28/xg28.dtsi:509 */
			interrupts = < 0xf 0x2 >,
			             < 0x10 0x2 >;        /* in zephyr/dts/arm/silabs/xg28/xg28.dtsi:510 */
			status = "disabled";              /* in zephyr/dts/arm/silabs/xg28/xg28.dtsi:511 */
		};

		/* node '/soc/sysrtc@500a8000' defined in zephyr/dts/arm/silabs/xg28/xg28.dtsi:514 */
		sysrtc0: sysrtc@500a8000 {
			compatible = "silabs,sysrtc";   /* in zephyr/dts/arm/silabs/xg28/xg28.dtsi:515 */
			reg = < 0x500a8000 0x4000 >;    /* in zephyr/dts/arm/silabs/xg28/xg28.dtsi:516 */
			clock-frequency = < 0x8000 >;   /* in zephyr/dts/arm/silabs/xg28/xg28.dtsi:517 */
			clocks = < &cmu 0x1e 0x13 >;    /* in zephyr/dts/arm/silabs/xg28/xg28.dtsi:518 */
			interrupt-names = "sysrtc_app",
			                  "sysrtc_seq"; /* in zephyr/dts/arm/silabs/xg28/xg28.dtsi:519 */
			interrupts = < 0x46 0x2 >,
			             < 0x47 0x2 >;      /* in zephyr/dts/arm/silabs/xg28/xg28.dtsi:520 */
			prescaler = < 0x1 >;            /* in zephyr/dts/arm/silabs/xg28/xg28.dtsi:521 */
			status = "okay";                /* in zephyr/boards/silabs/radio_boards/xg28_rb4401c/xg28_rb4401c.dts:238 */
		};

		/* node '/soc/letimer@59000000' defined in zephyr/dts/arm/silabs/xg28/xg28.dtsi:525 */
		letimer0: letimer@59000000 {
			compatible = "silabs,series2-letimer"; /* in zephyr/dts/arm/silabs/xg28/xg28.dtsi:526 */
			reg = < 0x59000000 0x4000 >;           /* in zephyr/dts/arm/silabs/xg28/xg28.dtsi:527 */
			clocks = < &cmu 0xc 0xc >;             /* in zephyr/dts/arm/silabs/xg28/xg28.dtsi:528 */
			interrupt-names = "letimer0";          /* in zephyr/dts/arm/silabs/xg28/xg28.dtsi:529 */
			interrupts = < 0x13 0x2 >;             /* in zephyr/dts/arm/silabs/xg28/xg28.dtsi:530 */
			status = "disabled";                   /* in zephyr/dts/arm/silabs/xg28/xg28.dtsi:531 */

			/* node '/soc/letimer@59000000/pwm' defined in zephyr/dts/arm/silabs/xg28/xg28.dtsi:533 */
			pwm {
				compatible = "silabs,letimer-pwm"; /* in zephyr/dts/arm/silabs/xg28/xg28.dtsi:534 */
				#pwm-cells = < 0x3 >;              /* in zephyr/dts/arm/silabs/xg28/xg28.dtsi:535 */
				status = "disabled";               /* in zephyr/dts/arm/silabs/xg28/xg28.dtsi:536 */
			};
		};

		/* node '/soc/adc@59004000' defined in zephyr/dts/arm/silabs/xg28/xg28.dtsi:540 */
		adc0: adc@59004000 {
			compatible = "silabs,iadc";  /* in zephyr/dts/arm/silabs/xg28/xg28.dtsi:541 */
			reg = < 0x59004000 0x4000 >; /* in zephyr/dts/arm/silabs/xg28/xg28.dtsi:542 */
			#io-channel-cells = < 0x1 >; /* in zephyr/dts/arm/silabs/xg28/xg28.dtsi:543 */
			clocks = < &cmu 0xa 0xf >;   /* in zephyr/dts/arm/silabs/xg28/xg28.dtsi:544 */
			interrupt-names = "iadc";    /* in zephyr/dts/arm/silabs/xg28/xg28.dtsi:545 */
			interrupts = < 0x32 0x2 >;   /* in zephyr/dts/arm/silabs/xg28/xg28.dtsi:546 */
			status = "disabled";         /* in zephyr/dts/arm/silabs/xg28/xg28.dtsi:547 */
		};

		/* node '/soc/acmp@59008000' defined in zephyr/dts/arm/silabs/xg28/xg28.dtsi:550 */
		acmp0: acmp@59008000 {
			compatible = "silabs,acmp";  /* in zephyr/dts/arm/silabs/xg28/xg28.dtsi:551 */
			reg = < 0x59008000 0x4000 >; /* in zephyr/dts/arm/silabs/xg28/xg28.dtsi:552 */
			clocks = < &cmu 0x52 0x23 >; /* in zephyr/dts/arm/silabs/xg28/xg28.dtsi:553 */
			interrupt-names = "acmp0";   /* in zephyr/dts/arm/silabs/xg28/xg28.dtsi:554 */
			interrupts = < 0x29 0x2 >;   /* in zephyr/dts/arm/silabs/xg28/xg28.dtsi:555 */
			status = "disabled";         /* in zephyr/dts/arm/silabs/xg28/xg28.dtsi:556 */
		};

		/* node '/soc/acmp@5900c000' defined in zephyr/dts/arm/silabs/xg28/xg28.dtsi:559 */
		acmp1: acmp@5900c000 {
			compatible = "silabs,acmp";  /* in zephyr/dts/arm/silabs/xg28/xg28.dtsi:560 */
			reg = < 0x5900c000 0x4000 >; /* in zephyr/dts/arm/silabs/xg28/xg28.dtsi:561 */
			clocks = < &cmu 0x53 0x23 >; /* in zephyr/dts/arm/silabs/xg28/xg28.dtsi:562 */
			interrupt-names = "acmp1";   /* in zephyr/dts/arm/silabs/xg28/xg28.dtsi:563 */
			interrupts = < 0x2a 0x2 >;   /* in zephyr/dts/arm/silabs/xg28/xg28.dtsi:564 */
			status = "disabled";         /* in zephyr/dts/arm/silabs/xg28/xg28.dtsi:565 */
		};

		/* node '/soc/vdac@59024000' defined in zephyr/dts/arm/silabs/xg28/xg28.dtsi:568 */
		vdac0: vdac@59024000 {
			compatible = "silabs,vdac";  /* in zephyr/dts/arm/silabs/xg28/xg28.dtsi:569 */
			reg = < 0x59024000 0x4000 >; /* in zephyr/dts/arm/silabs/xg28/xg28.dtsi:570 */
			#address-cells = < 0x1 >;    /* in zephyr/dts/arm/silabs/xg28/xg28.dtsi:571 */
			#io-channel-cells = < 0x1 >; /* in zephyr/dts/arm/silabs/xg28/xg28.dtsi:572 */
			#size-cells = < 0x0 >;       /* in zephyr/dts/arm/silabs/xg28/xg28.dtsi:573 */
			clocks = < &cmu 0x54 0x23 >; /* in zephyr/dts/arm/silabs/xg28/xg28.dtsi:574 */
			interrupt-names = "vdac0";   /* in zephyr/dts/arm/silabs/xg28/xg28.dtsi:575 */
			interrupts = < 0x37 0x2 >;   /* in zephyr/dts/arm/silabs/xg28/xg28.dtsi:576 */
			status = "disabled";         /* in zephyr/dts/arm/silabs/xg28/xg28.dtsi:577 */

			/* node '/soc/vdac@59024000/channel@0' defined in zephyr/dts/arm/silabs/xg28/xg28.dtsi:579 */
			channel@0 {
				reg = < 0x0 >; /* in zephyr/dts/arm/silabs/xg28/xg28.dtsi:580 */
			};

			/* node '/soc/vdac@59024000/channel@1' defined in zephyr/dts/arm/silabs/xg28/xg28.dtsi:583 */
			channel@1 {
				reg = < 0x1 >; /* in zephyr/dts/arm/silabs/xg28/xg28.dtsi:584 */
			};
		};

		/* node '/soc/hfrcoem23@5a000000' defined in zephyr/dts/arm/silabs/xg28/xg28.dtsi:588 */
		hfrcoem23: hfrcoem23@5a000000 {
			compatible = "silabs,series2-hfrcoem23"; /* in zephyr/dts/arm/silabs/xg28/xg28.dtsi:589 */
			reg = < 0x5a000000 0x4000 >;             /* in zephyr/dts/arm/silabs/xg28/xg28.dtsi:590 */
			#clock-cells = < 0x0 >;                  /* in zephyr/dts/arm/silabs/xg28/xg28.dtsi:591 */
			clock-frequency = < 0x121eac0 >;         /* in zephyr/dts/arm/silabs/xg28/xg28.dtsi:592 */
			clocks = < &cmu 0x13 0x23 >;             /* in zephyr/dts/arm/silabs/xg28/xg28.dtsi:593 */
			interrupt-names = "hfrcoem23";           /* in zephyr/dts/arm/silabs/xg28/xg28.dtsi:594 */
			interrupts = < 0x2f 0x2 >;               /* in zephyr/dts/arm/silabs/xg28/xg28.dtsi:595 */
		};

		/* node '/soc/hfxo@5a004000' defined in zephyr/dts/arm/silabs/xg28/xg28.dtsi:598 */
		clk_hfxo: hfxo: hfxo@5a004000 {
			compatible = "silabs,hfxo";      /* in zephyr/dts/arm/silabs/xg28/xg28.dtsi:599 */
			reg = < 0x5a004000 0x4000 >;     /* in zephyr/dts/arm/silabs/xg28/xg28.dtsi:600 */
			#clock-cells = < 0x0 >;          /* in zephyr/dts/arm/silabs/xg28/xg28.dtsi:601 */
			clock-frequency = < 0x25317c0 >; /* in zephyr/dts/arm/silabs/xg28/xg28.dtsi:602 */
			clocks = < &cmu 0x14 0x23 >;     /* in zephyr/dts/arm/silabs/xg28/xg28.dtsi:603 */
			interrupt-names = "hfxo0";       /* in zephyr/dts/arm/silabs/xg28/xg28.dtsi:605 */
			interrupts = < 0x2d 0x2 >;       /* in zephyr/dts/arm/silabs/xg28/xg28.dtsi:606 */
			ctune = < 0x73 >;                /* in zephyr/boards/silabs/radio_boards/xg28_rb4401c/xg28_rb4401c.dts:222 */
			precision = < 0x32 >;            /* in zephyr/boards/silabs/radio_boards/xg28_rb4401c/xg28_rb4401c.dts:223 */
			status = "okay";                 /* in zephyr/boards/silabs/radio_boards/xg28_rb4401c/xg28_rb4401c.dts:224 */
			phandle = < 0x2 >;               /* in zephyr/boards/silabs/radio_boards/xg28_rb4401c/xg28_rb4401c.dts:213 */
		};

		/* node '/soc/i2c@5b000000' defined in zephyr/dts/arm/silabs/xg28/xg28.dtsi:611 */
		i2c0: i2c@5b000000 {
			compatible = "silabs,i2c";     /* in zephyr/dts/arm/silabs/xg28/xg28.dtsi:612 */
			reg = < 0x5b000000 0x4000 >;   /* in zephyr/dts/arm/silabs/xg28/xg28.dtsi:613 */
			#address-cells = < 0x1 >;      /* in zephyr/dts/arm/silabs/xg28/xg28.dtsi:614 */
			#size-cells = < 0x0 >;         /* in zephyr/dts/arm/silabs/xg28/xg28.dtsi:615 */
			clock-frequency = < 0x186a0 >; /* in zephyr/dts/arm/silabs/xg28/xg28.dtsi:616 */
			clocks = < &cmu 0xe 0x4 >;     /* in zephyr/dts/arm/silabs/xg28/xg28.dtsi:617 */
			interrupt-names = "i2c0";      /* in zephyr/dts/arm/silabs/xg28/xg28.dtsi:618 */
			interrupts = < 0x1c 0x2 >;     /* in zephyr/dts/arm/silabs/xg28/xg28.dtsi:619 */
			pinctrl-0 = < &i2c0_default >; /* in zephyr/boards/silabs/radio_boards/xg28_rb4401c/xg28_rb4401c.dts:174 */
			pinctrl-names = "default";     /* in zephyr/boards/silabs/radio_boards/xg28_rb4401c/xg28_rb4401c.dts:175 */
			status = "okay";               /* in zephyr/boards/silabs/radio_boards/xg28_rb4401c/xg28_rb4401c.dts:176 */

			/* node '/soc/i2c@5b000000/si7021@40' defined in zephyr/boards/silabs/radio_boards/xg28_rb4401c/xg28_rb4401c.dts:178 */
			si7021: si7021@40 {
				compatible = "silabs,si7006";         /* in zephyr/boards/silabs/radio_boards/xg28_rb4401c/xg28_rb4401c.dts:179 */
				reg = < 0x40 >;                       /* in zephyr/boards/silabs/radio_boards/xg28_rb4401c/xg28_rb4401c.dts:180 */
				vin-supply = < &sensor_disp_enable >; /* in zephyr/boards/silabs/radio_boards/xg28_rb4401c/xg28_rb4401c.dts:181 */
			};
		};

		/* node '/soc/wdog@5b004000' defined in zephyr/dts/arm/silabs/xg28/xg28.dtsi:623 */
		wdog0: wdog@5b004000 {
			compatible = "silabs,gecko-wdog"; /* in zephyr/dts/arm/silabs/xg28/xg28.dtsi:624 */
			reg = < 0x5b004000 0x4000 >;      /* in zephyr/dts/arm/silabs/xg28/xg28.dtsi:625 */
			clocks = < &cmu 0xd 0x10 >;       /* in zephyr/dts/arm/silabs/xg28/xg28.dtsi:626 */
			interrupt-names = "wdog0";        /* in zephyr/dts/arm/silabs/xg28/xg28.dtsi:627 */
			interrupts = < 0x2b 0x2 >;        /* in zephyr/dts/arm/silabs/xg28/xg28.dtsi:628 */
			peripheral-id = < 0x0 >;          /* in zephyr/dts/arm/silabs/xg28/xg28.dtsi:629 */
			status = "okay";                  /* in zephyr/boards/silabs/radio_boards/xg28_rb4401c/xg28_rb4401c.dts:256 */
		};

		/* node '/soc/wdog@5b008000' defined in zephyr/dts/arm/silabs/xg28/xg28.dtsi:633 */
		wdog1: wdog@5b008000 {
			compatible = "silabs,gecko-wdog"; /* in zephyr/dts/arm/silabs/xg28/xg28.dtsi:634 */
			reg = < 0x5b008000 0x4000 >;      /* in zephyr/dts/arm/silabs/xg28/xg28.dtsi:635 */
			clocks = < &cmu 0x51 0x11 >;      /* in zephyr/dts/arm/silabs/xg28/xg28.dtsi:636 */
			interrupt-names = "wdog1";        /* in zephyr/dts/arm/silabs/xg28/xg28.dtsi:637 */
			interrupts = < 0x2c 0x2 >;        /* in zephyr/dts/arm/silabs/xg28/xg28.dtsi:638 */
			peripheral-id = < 0x1 >;          /* in zephyr/dts/arm/silabs/xg28/xg28.dtsi:639 */
			status = "disabled";              /* in zephyr/dts/arm/silabs/xg28/xg28.dtsi:640 */
		};

		/* node '/soc/eusart@5b010000' defined in zephyr/dts/arm/silabs/xg28/xg28.dtsi:643 */
		eusart0: eusart@5b010000 {
			compatible = "silabs,eusart-spi"; /* in zephyr/dts/arm/silabs/xg28/xg28.dtsi:644 */
			reg = < 0x5b010000 0x4000 >;      /* in zephyr/dts/arm/silabs/xg28/xg28.dtsi:645 */
			clocks = < &cmu 0x56 0x15 >;      /* in zephyr/dts/arm/silabs/xg28/xg28.dtsi:646 */
			interrupt-names = "rx",
			                  "tx";           /* in zephyr/dts/arm/silabs/xg28/xg28.dtsi:647 */
			interrupts = < 0xb 0x2 >,
			             < 0xc 0x2 >;         /* in zephyr/dts/arm/silabs/xg28/xg28.dtsi:648 */
			status = "disabled";              /* in zephyr/dts/arm/silabs/xg28/xg28.dtsi:649 */
		};

		/* node '/soc/semailbox@5c000000' defined in zephyr/dts/arm/silabs/xg28/xg28.dtsi:652 */
		se: semailbox@5c000000 {
			compatible = "silabs,gecko-semailbox"; /* in zephyr/dts/arm/silabs/xg28/xg28.dtsi:653 */
			reg = < 0x5c000000 0x4000 >;           /* in zephyr/dts/arm/silabs/xg28/xg28.dtsi:654 */
			interrupt-names = "setamperhost",
			                  "sembrx",
			                  "sembtx";            /* in zephyr/dts/arm/silabs/xg28/xg28.dtsi:655 */
			interrupts = < 0x42 0x2 >,
			             < 0x43 0x2 >,
			             < 0x44 0x2 >;             /* in zephyr/dts/arm/silabs/xg28/xg28.dtsi:656 */
			status = "okay";                       /* in zephyr/boards/silabs/radio_boards/xg28_rb4401c/xg28_rb4401c.dts:234 */
		};

		/* node '/soc/radio@b0000000' defined in zephyr/dts/arm/silabs/xg28/efr32xg28.dtsi:11 */
		radio: radio@b0000000 {
			compatible = "silabs,series2-radio"; /* in zephyr/dts/arm/silabs/xg28/efr32xg28.dtsi:12 */
			reg = < 0xb0000000 0x1000000 >;      /* in zephyr/dts/arm/silabs/xg28/efr32xg28.dtsi:13 */
			interrupt-names = "agc",
			                  "bufc",
			                  "frc_pri",
			                  "frc",
			                  "modem",
			                  "protimer",
			                  "rac_rsm",
			                  "rac_seq",
			                  "hostmailbox",
			                  "synth",
			                  "rfeca0",
			                  "rfeca1";          /* in zephyr/dts/arm/silabs/xg28/efr32xg28.dtsi:14 */
			interrupts = < 0x1f 0x1 >,
			             < 0x20 0x1 >,
			             < 0x21 0x1 >,
			             < 0x22 0x1 >,
			             < 0x23 0x1 >,
			             < 0x24 0x1 >,
			             < 0x25 0x1 >,
			             < 0x26 0x1 >,
			             < 0x27 0x1 >,
			             < 0x28 0x1 >,
			             < 0x4a 0x1 >,
			             < 0x4b 0x1 >;           /* in zephyr/dts/arm/silabs/xg28/efr32xg28.dtsi:17 */
			pa-2p4ghz = "highest";               /* in zephyr/dts/arm/silabs/xg28/efr32xg28.dtsi:19 */
			pa-initial-power-dbm = < 0xa >;      /* in zephyr/dts/arm/silabs/xg28/efr32xg28.dtsi:20 */
			pa-ramp-time-us = < 0xa >;           /* in zephyr/dts/arm/silabs/xg28/efr32xg28.dtsi:21 */
			pa-subghz = "highest";               /* in zephyr/dts/arm/silabs/xg28/efr32xg28.dtsi:22 */
			pa-voltage-mv = < 0xce4 >;           /* in zephyr/dts/arm/silabs/xg28/efr32xg28.dtsi:23 */

			/* node '/soc/radio@b0000000/pti' defined in zephyr/dts/arm/silabs/xg28/efr32xg28.dtsi:25 */
			pti: pti {
				compatible = "silabs,pti";      /* in zephyr/dts/arm/silabs/xg28/efr32xg28.dtsi:26 */
				clock-frequency = < 0x186a00 >; /* in zephyr/dts/arm/silabs/xg28/efr32xg28.dtsi:27 */
				mode = "uart";                  /* in zephyr/dts/arm/silabs/xg28/efr32xg28.dtsi:28 */
				status = "disabled";            /* in zephyr/dts/arm/silabs/xg28/efr32xg28.dtsi:29 */
			};

			/* node '/soc/radio@b0000000/bt_hci_silabs' defined in zephyr/dts/arm/silabs/xg28/efr32zg28.dtsi:10 */
			bt_hci_silabs: bt_hci_silabs {
				compatible = "silabs,bt-hci-efr32"; /* in zephyr/dts/arm/silabs/xg28/efr32zg28.dtsi:11 */
				status = "okay";                    /* in zephyr/boards/silabs/radio_boards/xg28_rb4401c/xg28_rb4401c.dts:112 */
			};
		};
	};

	/* node '/clocks' defined in zephyr/dts/arm/silabs/xg28/xg28.dtsi:23 */
	clocks {

		/* node '/clocks/em01grpaclk' defined in zephyr/dts/arm/silabs/xg28/xg28.dtsi:24 */
		em01grpaclk: em01grpaclk {
			compatible = "fixed-factor-clock"; /* in zephyr/dts/arm/silabs/xg28/xg28.dtsi:25 */
			#clock-cells = < 0x0 >;            /* in zephyr/dts/arm/silabs/xg28/xg28.dtsi:26 */
			clocks = < &hfrcodpll >;           /* in zephyr/dts/arm/silabs/xg28/xg28.dtsi:27 */
			phandle = < 0xf >;                 /* in zephyr/dts/arm/silabs/xg28/xg28.dtsi:83 */
		};

		/* node '/clocks/em01grpcclk' defined in zephyr/dts/arm/silabs/xg28/xg28.dtsi:30 */
		em01grpcclk: em01grpcclk {
			compatible = "fixed-factor-clock"; /* in zephyr/dts/arm/silabs/xg28/xg28.dtsi:31 */
			#clock-cells = < 0x0 >;            /* in zephyr/dts/arm/silabs/xg28/xg28.dtsi:32 */
			clocks = < &hfrcodpll >;           /* in zephyr/dts/arm/silabs/xg28/xg28.dtsi:33 */
			phandle = < 0xc >;                 /* in zephyr/dts/arm/silabs/xg28/xg28.dtsi:51 */
		};

		/* node '/clocks/em23grpaclk' defined in zephyr/dts/arm/silabs/xg28/xg28.dtsi:36 */
		em23grpaclk: em23grpaclk {
			compatible = "fixed-factor-clock"; /* in zephyr/dts/arm/silabs/xg28/xg28.dtsi:37 */
			#clock-cells = < 0x0 >;            /* in zephyr/dts/arm/silabs/xg28/xg28.dtsi:38 */
			clocks = < &lfxo >;                /* in zephyr/boards/silabs/radio_boards/xg28_rb4401c/xg28_rb4401c.dts:127 */
			phandle = < 0x13 >;                /* in zephyr/dts/arm/silabs/xg28/xg28.dtsi:115 */
		};

		/* node '/clocks/em4grpaclk' defined in zephyr/dts/arm/silabs/xg28/xg28.dtsi:42 */
		em4grpaclk: em4grpaclk {
			compatible = "fixed-factor-clock"; /* in zephyr/dts/arm/silabs/xg28/xg28.dtsi:43 */
			#clock-cells = < 0x0 >;            /* in zephyr/dts/arm/silabs/xg28/xg28.dtsi:44 */
			clocks = < &lfxo >;                /* in zephyr/boards/silabs/radio_boards/xg28_rb4401c/xg28_rb4401c.dts:131 */
		};

		/* node '/clocks/eusart0clk' defined in zephyr/dts/arm/silabs/xg28/xg28.dtsi:48 */
		eusart0clk: eusart0clk {
			compatible = "fixed-factor-clock"; /* in zephyr/dts/arm/silabs/xg28/xg28.dtsi:49 */
			#clock-cells = < 0x0 >;            /* in zephyr/dts/arm/silabs/xg28/xg28.dtsi:50 */
			clocks = < &em01grpcclk >;         /* in zephyr/dts/arm/silabs/xg28/xg28.dtsi:51 */
		};

		/* node '/clocks/hclk' defined in zephyr/dts/arm/silabs/xg28/xg28.dtsi:54 */
		hclk: hclk {
			compatible = "fixed-factor-clock"; /* in zephyr/dts/arm/silabs/xg28/xg28.dtsi:55 */
			#clock-cells = < 0x0 >;            /* in zephyr/dts/arm/silabs/xg28/xg28.dtsi:56 */
			clock-div = < 0x1 >;               /* in zephyr/dts/arm/silabs/xg28/xg28.dtsi:57 */
			clocks = < &sysclk >;              /* in zephyr/dts/arm/silabs/xg28/xg28.dtsi:58 */
			phandle = < 0xe >;                 /* in zephyr/dts/arm/silabs/xg28/xg28.dtsi:65 */
		};

		/* node '/clocks/hclkdiv1024' defined in zephyr/dts/arm/silabs/xg28/xg28.dtsi:61 */
		hclkdiv1024: hclkdiv1024 {
			compatible = "fixed-factor-clock"; /* in zephyr/dts/arm/silabs/xg28/xg28.dtsi:62 */
			#clock-cells = < 0x0 >;            /* in zephyr/dts/arm/silabs/xg28/xg28.dtsi:63 */
			clock-div = < 0x400 >;             /* in zephyr/dts/arm/silabs/xg28/xg28.dtsi:64 */
			clocks = < &hclk >;                /* in zephyr/dts/arm/silabs/xg28/xg28.dtsi:65 */
		};

		/* node '/clocks/hfrcodpllrt' defined in zephyr/dts/arm/silabs/xg28/xg28.dtsi:68 */
		hfrcodpllrt: hfrcodpllrt {
			compatible = "fixed-factor-clock"; /* in zephyr/dts/arm/silabs/xg28/xg28.dtsi:69 */
			#clock-cells = < 0x0 >;            /* in zephyr/dts/arm/silabs/xg28/xg28.dtsi:70 */
			clocks = < &hfrcodpll >;           /* in zephyr/dts/arm/silabs/xg28/xg28.dtsi:71 */
		};

		/* node '/clocks/hfxort' defined in zephyr/dts/arm/silabs/xg28/xg28.dtsi:74 */
		hfxort: hfxort {
			compatible = "fixed-factor-clock"; /* in zephyr/dts/arm/silabs/xg28/xg28.dtsi:75 */
			#clock-cells = < 0x0 >;            /* in zephyr/dts/arm/silabs/xg28/xg28.dtsi:76 */
			clocks = < &hfxo >;                /* in zephyr/dts/arm/silabs/xg28/xg28.dtsi:77 */
		};

		/* node '/clocks/iadcclk' defined in zephyr/dts/arm/silabs/xg28/xg28.dtsi:80 */
		iadcclk: iadcclk {
			compatible = "fixed-factor-clock"; /* in zephyr/dts/arm/silabs/xg28/xg28.dtsi:81 */
			#clock-cells = < 0x0 >;            /* in zephyr/dts/arm/silabs/xg28/xg28.dtsi:82 */
			clocks = < &em01grpaclk >;         /* in zephyr/dts/arm/silabs/xg28/xg28.dtsi:83 */
		};

		/* node '/clocks/lcdclk' defined in zephyr/dts/arm/silabs/xg28/xg28.dtsi:86 */
		lcdclk: lcdclk {
			compatible = "fixed-factor-clock"; /* in zephyr/dts/arm/silabs/xg28/xg28.dtsi:87 */
			#clock-cells = < 0x0 >;            /* in zephyr/dts/arm/silabs/xg28/xg28.dtsi:88 */
			clocks = < &lfrco >;               /* in zephyr/dts/arm/silabs/xg28/xg28.dtsi:89 */
		};

		/* node '/clocks/lesensehfclk' defined in zephyr/dts/arm/silabs/xg28/xg28.dtsi:92 */
		lesensehfclk: lesensehfclk {
			compatible = "fixed-factor-clock"; /* in zephyr/dts/arm/silabs/xg28/xg28.dtsi:93 */
			#clock-cells = < 0x0 >;            /* in zephyr/dts/arm/silabs/xg28/xg28.dtsi:94 */
			clocks = < &fsrco >;               /* in zephyr/dts/arm/silabs/xg28/xg28.dtsi:95 */
		};

		/* node '/clocks/lspclk' defined in zephyr/dts/arm/silabs/xg28/xg28.dtsi:98 */
		lspclk: lspclk {
			compatible = "fixed-factor-clock"; /* in zephyr/dts/arm/silabs/xg28/xg28.dtsi:99 */
			#clock-cells = < 0x0 >;            /* in zephyr/dts/arm/silabs/xg28/xg28.dtsi:100 */
			clock-div = < 0x2 >;               /* in zephyr/dts/arm/silabs/xg28/xg28.dtsi:101 */
			clocks = < &pclk >;                /* in zephyr/dts/arm/silabs/xg28/xg28.dtsi:102 */
		};

		/* node '/clocks/pclk' defined in zephyr/dts/arm/silabs/xg28/xg28.dtsi:105 */
		pclk: pclk {
			compatible = "fixed-factor-clock"; /* in zephyr/dts/arm/silabs/xg28/xg28.dtsi:106 */
			#clock-cells = < 0x0 >;            /* in zephyr/dts/arm/silabs/xg28/xg28.dtsi:107 */
			clock-div = < 0x2 >;               /* in zephyr/dts/arm/silabs/xg28/xg28.dtsi:108 */
			clocks = < &hclk >;                /* in zephyr/dts/arm/silabs/xg28/xg28.dtsi:109 */
			phandle = < 0x12 >;                /* in zephyr/dts/arm/silabs/xg28/xg28.dtsi:102 */
		};

		/* node '/clocks/pcnt0clk' defined in zephyr/dts/arm/silabs/xg28/xg28.dtsi:112 */
		pcnt0clk: pcnt0clk {
			compatible = "fixed-factor-clock"; /* in zephyr/dts/arm/silabs/xg28/xg28.dtsi:113 */
			#clock-cells = < 0x0 >;            /* in zephyr/dts/arm/silabs/xg28/xg28.dtsi:114 */
			clocks = < &em23grpaclk >;         /* in zephyr/dts/arm/silabs/xg28/xg28.dtsi:115 */
		};

		/* node '/clocks/sysclk' defined in zephyr/dts/arm/silabs/xg28/xg28.dtsi:118 */
		sysclk: sysclk {
			compatible = "fixed-factor-clock"; /* in zephyr/dts/arm/silabs/xg28/xg28.dtsi:119 */
			#clock-cells = < 0x0 >;            /* in zephyr/dts/arm/silabs/xg28/xg28.dtsi:120 */
			clocks = < &hfrcodpll >;           /* in zephyr/dts/arm/silabs/xg28/xg28.dtsi:121 */
			phandle = < 0xd >;                 /* in zephyr/dts/arm/silabs/xg28/xg28.dtsi:58 */
		};

		/* node '/clocks/sysrtcclk' defined in zephyr/dts/arm/silabs/xg28/xg28.dtsi:124 */
		sysrtcclk: sysrtcclk {
			compatible = "fixed-factor-clock"; /* in zephyr/dts/arm/silabs/xg28/xg28.dtsi:125 */
			#clock-cells = < 0x0 >;            /* in zephyr/dts/arm/silabs/xg28/xg28.dtsi:126 */
			clocks = < &lfxo >;                /* in zephyr/boards/silabs/radio_boards/xg28_rb4401c/xg28_rb4401c.dts:242 */
		};

		/* node '/clocks/systickclk' defined in zephyr/dts/arm/silabs/xg28/xg28.dtsi:130 */
		systickclk: systickclk {
			compatible = "fixed-factor-clock"; /* in zephyr/dts/arm/silabs/xg28/xg28.dtsi:131 */
			#clock-cells = < 0x0 >;            /* in zephyr/dts/arm/silabs/xg28/xg28.dtsi:132 */
			clocks = < &hclk >;                /* in zephyr/dts/arm/silabs/xg28/xg28.dtsi:133 */
		};

		/* node '/clocks/traceclk' defined in zephyr/dts/arm/silabs/xg28/xg28.dtsi:136 */
		traceclk: traceclk {
			compatible = "fixed-factor-clock"; /* in zephyr/dts/arm/silabs/xg28/xg28.dtsi:137 */
			#clock-cells = < 0x0 >;            /* in zephyr/dts/arm/silabs/xg28/xg28.dtsi:138 */
			clock-div = < 0x1 >;               /* in zephyr/dts/arm/silabs/xg28/xg28.dtsi:139 */
			clocks = < &sysclk >;              /* in zephyr/dts/arm/silabs/xg28/xg28.dtsi:140 */
		};

		/* node '/clocks/vdac0clk' defined in zephyr/dts/arm/silabs/xg28/xg28.dtsi:143 */
		vdac0clk: vdac0clk {
			compatible = "fixed-factor-clock"; /* in zephyr/dts/arm/silabs/xg28/xg28.dtsi:144 */
			#clock-cells = < 0x0 >;            /* in zephyr/dts/arm/silabs/xg28/xg28.dtsi:145 */
			clocks = < &em01grpaclk >;         /* in zephyr/dts/arm/silabs/xg28/xg28.dtsi:146 */
		};

		/* node '/clocks/wdog0clk' defined in zephyr/dts/arm/silabs/xg28/xg28.dtsi:149 */
		wdog0clk: wdog0clk {
			compatible = "fixed-factor-clock"; /* in zephyr/dts/arm/silabs/xg28/xg28.dtsi:150 */
			#clock-cells = < 0x0 >;            /* in zephyr/dts/arm/silabs/xg28/xg28.dtsi:151 */
			clocks = < &lfxo >;                /* in zephyr/boards/silabs/radio_boards/xg28_rb4401c/xg28_rb4401c.dts:260 */
		};

		/* node '/clocks/wdog1clk' defined in zephyr/dts/arm/silabs/xg28/xg28.dtsi:155 */
		wdog1clk: wdog1clk {
			compatible = "fixed-factor-clock"; /* in zephyr/dts/arm/silabs/xg28/xg28.dtsi:156 */
			#clock-cells = < 0x0 >;            /* in zephyr/dts/arm/silabs/xg28/xg28.dtsi:157 */
			clocks = < &lfxo >;                /* in zephyr/boards/silabs/radio_boards/xg28_rb4401c/xg28_rb4401c.dts:264 */
		};
	};

	/* node '/cpus' defined in zephyr/dts/arm/silabs/xg28/xg28.dtsi:162 */
	cpus {
		#address-cells = < 0x1 >; /* in zephyr/dts/arm/silabs/xg28/xg28.dtsi:163 */
		#size-cells = < 0x0 >;    /* in zephyr/dts/arm/silabs/xg28/xg28.dtsi:164 */

		/* node '/cpus/cpu@0' defined in zephyr/dts/arm/silabs/xg28/xg28.dtsi:166 */
		cpu0: cpu@0 {
			compatible = "arm,cortex-m33";                              /* in zephyr/dts/arm/silabs/xg28/xg28.dtsi:167 */
			reg = < 0x0 >;                                              /* in zephyr/dts/arm/silabs/xg28/xg28.dtsi:168 */
			#address-cells = < 0x1 >;                                   /* in zephyr/dts/arm/silabs/xg28/xg28.dtsi:169 */
			#size-cells = < 0x1 >;                                      /* in zephyr/dts/arm/silabs/xg28/xg28.dtsi:170 */
			cpu-power-states = < &pstate_em1 &pstate_em2 &pstate_em4 >; /* in zephyr/dts/arm/silabs/xg28/xg28.dtsi:175 */
			device_type = "cpu";                                        /* in zephyr/dts/arm/silabs/xg28/xg28.dtsi:176 */
			clock-frequency = < 0x4a62f80 >;                            /* in zephyr/boards/silabs/radio_boards/xg28_rb4401c/xg28_rb4401c.dts:116 */

			/* node '/cpus/cpu@0/itm@e0000000' defined in zephyr/dts/arm/silabs/xg28/xg28.dtsi:178 */
			itm: itm@e0000000 {
				compatible = "arm,armv8m-itm"; /* in zephyr/dts/arm/silabs/xg28/xg28.dtsi:179 */
				reg = < 0xe0000000 0x1000 >;   /* in zephyr/dts/arm/silabs/xg28/xg28.dtsi:180 */
			};

			/* node '/cpus/cpu@0/mpu@e000ed90' defined in zephyr/dts/arm/silabs/xg28/xg28.dtsi:183 */
			mpu: mpu@e000ed90 {
				compatible = "arm,armv8m-mpu"; /* in zephyr/dts/arm/silabs/xg28/xg28.dtsi:184 */
				reg = < 0xe000ed90 0x40 >;     /* in zephyr/dts/arm/silabs/xg28/xg28.dtsi:185 */
			};
		};

		/* node '/cpus/power-states' defined in zephyr/dts/arm/silabs/xg28/xg28.dtsi:189 */
		power-states {

			/* node '/cpus/power-states/em1' defined in zephyr/dts/arm/silabs/xg28/xg28.dtsi:190 */
			pstate_em1: em1 {
				compatible = "zephyr,power-state"; /* in zephyr/dts/arm/silabs/xg28/xg28.dtsi:191 */
				power-state-name = "runtime-idle"; /* in zephyr/dts/arm/silabs/xg28/xg28.dtsi:192 */
				phandle = < 0x14 >;                /* in zephyr/dts/arm/silabs/xg28/xg28.dtsi:175 */
			};

			/* node '/cpus/power-states/em2' defined in zephyr/dts/arm/silabs/xg28/xg28.dtsi:195 */
			pstate_em2: em2 {
				compatible = "zephyr,power-state";    /* in zephyr/dts/arm/silabs/xg28/xg28.dtsi:196 */
				power-state-name = "suspend-to-idle"; /* in zephyr/dts/arm/silabs/xg28/xg28.dtsi:197 */
				phandle = < 0x15 >;                   /* in zephyr/dts/arm/silabs/xg28/xg28.dtsi:175 */
			};

			/* node '/cpus/power-states/em4' defined in zephyr/dts/arm/silabs/xg28/xg28.dtsi:200 */
			pstate_em4: em4 {
				compatible = "zephyr,power-state"; /* in zephyr/dts/arm/silabs/xg28/xg28.dtsi:201 */
				power-state-name = "soft-off";     /* in zephyr/dts/arm/silabs/xg28/xg28.dtsi:202 */
				status = "disabled";               /* in zephyr/dts/arm/silabs/xg28/xg28.dtsi:203 */
				phandle = < 0x16 >;                /* in zephyr/dts/arm/silabs/xg28/xg28.dtsi:175 */
			};
		};
	};

	/* node '/hwinfo' defined in zephyr/dts/arm/silabs/xg28/xg28.dtsi:208 */
	hwinfo: hwinfo {
		compatible = "silabs,series2-hwinfo"; /* in zephyr/dts/arm/silabs/xg28/xg28.dtsi:209 */
		status = "disabled";                  /* in zephyr/dts/arm/silabs/xg28/xg28.dtsi:210 */
	};

	/* node '/memory@20000000' defined in zephyr/dts/arm/silabs/xg28/xg28.dtsi:661 */
	sram0: memory@20000000 {
		compatible = "mmio-sram";     /* in zephyr/dts/arm/silabs/xg28/xg28.dtsi:662 */
		device_type = "memory";       /* in zephyr/dts/arm/silabs/xg28/xg28.dtsi:663 */
		reg = < 0x20000000 0x40000 >; /* in zephyr/dts/arm/silabs/xg28/efr32zg28b322f1024im68.dtsi:23 */
	};

	/* node '/buttons' defined in zephyr/boards/silabs/radio_boards/xg28_rb4401c/xg28_rb4401c.dts:40 */
	buttons {
		compatible = "gpio-keys"; /* in zephyr/boards/silabs/radio_boards/xg28_rb4401c/xg28_rb4401c.dts:41 */

		/* node '/buttons/button_0' defined in zephyr/boards/silabs/radio_boards/xg28_rb4401c/xg28_rb4401c.dts:43 */
		button0: button_0 {
			gpios = < &gpiob 0x1 0x1 >;   /* in zephyr/boards/silabs/radio_boards/xg28_rb4401c/xg28_rb4401c.dts:44 */
			label = "User Push Button 0"; /* in zephyr/boards/silabs/radio_boards/xg28_rb4401c/xg28_rb4401c.dts:45 */
			zephyr,code = < 0xb >;        /* in zephyr/boards/silabs/radio_boards/xg28_rb4401c/xg28_rb4401c.dts:46 */
		};

		/* node '/buttons/button_1' defined in zephyr/boards/silabs/radio_boards/xg28_rb4401c/xg28_rb4401c.dts:49 */
		button1: button_1 {
			gpios = < &gpiob 0x3 0x1 >;   /* in zephyr/boards/silabs/radio_boards/xg28_rb4401c/xg28_rb4401c.dts:50 */
			label = "User Push Button 1"; /* in zephyr/boards/silabs/radio_boards/xg28_rb4401c/xg28_rb4401c.dts:51 */
			zephyr,code = < 0x2 >;        /* in zephyr/boards/silabs/radio_boards/xg28_rb4401c/xg28_rb4401c.dts:52 */
		};
	};

	/* node '/leds' defined in zephyr/boards/silabs/radio_boards/xg28_rb4401c/xg28_rb4401c.dts:56 */
	leds {
		compatible = "gpio-leds"; /* in zephyr/boards/silabs/radio_boards/xg28_rb4401c/xg28_rb4401c.dts:57 */

		/* node '/leds/led_0' defined in zephyr/boards/silabs/radio_boards/xg28_rb4401c/xg28_rb4401c.dts:59 */
		led0: led_0 {
			gpios = < &gpiob 0x2 0x0 >; /* in zephyr/boards/silabs/radio_boards/xg28_rb4401c/xg28_rb4401c.dts:60 */
			label = "LED 0";            /* in zephyr/boards/silabs/radio_boards/xg28_rb4401c/xg28_rb4401c.dts:61 */
		};

		/* node '/leds/led_1' defined in zephyr/boards/silabs/radio_boards/xg28_rb4401c/xg28_rb4401c.dts:64 */
		led1: led_1 {
			gpios = < &gpiod 0x3 0x0 >; /* in zephyr/boards/silabs/radio_boards/xg28_rb4401c/xg28_rb4401c.dts:65 */
			label = "LED 1";            /* in zephyr/boards/silabs/radio_boards/xg28_rb4401c/xg28_rb4401c.dts:66 */
		};
	};

	/* node '/pwmleds' defined in zephyr/boards/silabs/radio_boards/xg28_rb4401c/xg28_rb4401c.dts:70 */
	pwmleds {
		compatible = "pwm-leds"; /* in zephyr/boards/silabs/radio_boards/xg28_rb4401c/xg28_rb4401c.dts:71 */

		/* node '/pwmleds/pwm_led_0' defined in zephyr/boards/silabs/radio_boards/xg28_rb4401c/xg28_rb4401c.dts:73 */
		pwm_led0: pwm_led_0 {
			pwms = < &timer0_pwm 0x0 0x1312d00 0x0 >; /* in zephyr/boards/silabs/radio_boards/xg28_rb4401c/xg28_rb4401c.dts:74 */
		};

		/* node '/pwmleds/pwm_led_1' defined in zephyr/boards/silabs/radio_boards/xg28_rb4401c/xg28_rb4401c.dts:77 */
		pwm_led1: pwm_led_1 {
			pwms = < &timer0_pwm 0x1 0x1312d00 0x0 >; /* in zephyr/boards/silabs/radio_boards/xg28_rb4401c/xg28_rb4401c.dts:78 */
		};
	};

	/* node '/sensor_disp_enable' defined in zephyr/boards/silabs/radio_boards/xg28_rb4401c/xg28_rb4401c.dts:82 */
	sensor_disp_enable: sensor_disp_enable {
		compatible = "regulator-fixed";        /* in zephyr/boards/silabs/radio_boards/xg28_rb4401c/xg28_rb4401c.dts:83 */
		enable-gpios = < &gpioc 0xb 0x0 >;     /* in zephyr/boards/silabs/radio_boards/xg28_rb4401c/xg28_rb4401c.dts:84 */
		regulator-name = "sensor_disp_enable"; /* in zephyr/boards/silabs/radio_boards/xg28_rb4401c/xg28_rb4401c.dts:85 */
		status = "okay";                       /* in zephyr/boards/silabs/radio_boards/xg28_rb4401c/xg28_rb4401c.dts:86 */
		phandle = < 0x9 >;                     /* in zephyr/boards/silabs/radio_boards/xg28_rb4401c/xg28_rb4401c.dts:181 */
	};

	/* node '/exp-header' defined in zephyr/boards/silabs/radio_boards/xg28_rb4401c/xg28_rb4401c.dts:89 */
	exp_header: exp-header {
		compatible = "silabs,exp-header";       /* in zephyr/boards/silabs/radio_boards/xg28_rb4401c/xg28_rb4401c.dts:90 */
		#gpio-cells = < 0x2 >;                  /* in zephyr/boards/silabs/radio_boards/xg28_rb4401c/xg28_rb4401c.dts:91 */
		gpio-map = < 0x3 0x0 &gpioa 0xb 0x0 >,
		           < 0x4 0x0 &gpiod 0x7 0x0 >,
		           < 0x5 0x0 &gpioa 0xc 0x0 >,
		           < 0x6 0x0 &gpiod 0x8 0x0 >,
		           < 0x7 0x0 &gpioa 0xd 0x0 >,
		           < 0x8 0x0 &gpiod 0x9 0x0 >,
		           < 0x9 0x0 &gpioa 0xe 0x0 >,
		           < 0xa 0x0 &gpiod 0xa 0x0 >,
		           < 0xb 0x0 &gpiob 0x4 0x0 >,
		           < 0xc 0x0 &gpiod 0xb 0x0 >,
		           < 0xd 0x0 &gpiob 0x5 0x0 >,
		           < 0xe 0x0 &gpiod 0xc 0x0 >,
		           < 0xf 0x0 &gpioc 0x5 0x0 >,
		           < 0x10 0x0 &gpioc 0x7 0x0 >; /* in zephyr/boards/silabs/radio_boards/xg28_rb4401c/xg28_rb4401c.dts:92 */
		gpio-map-mask = < 0xffffffff 0x0 >;     /* in zephyr/boards/silabs/radio_boards/xg28_rb4401c/xg28_rb4401c.dts:106 */
		gpio-map-pass-thru = < 0x0 0x7f >;      /* in zephyr/boards/silabs/radio_boards/xg28_rb4401c/xg28_rb4401c.dts:107 */
	};
};
